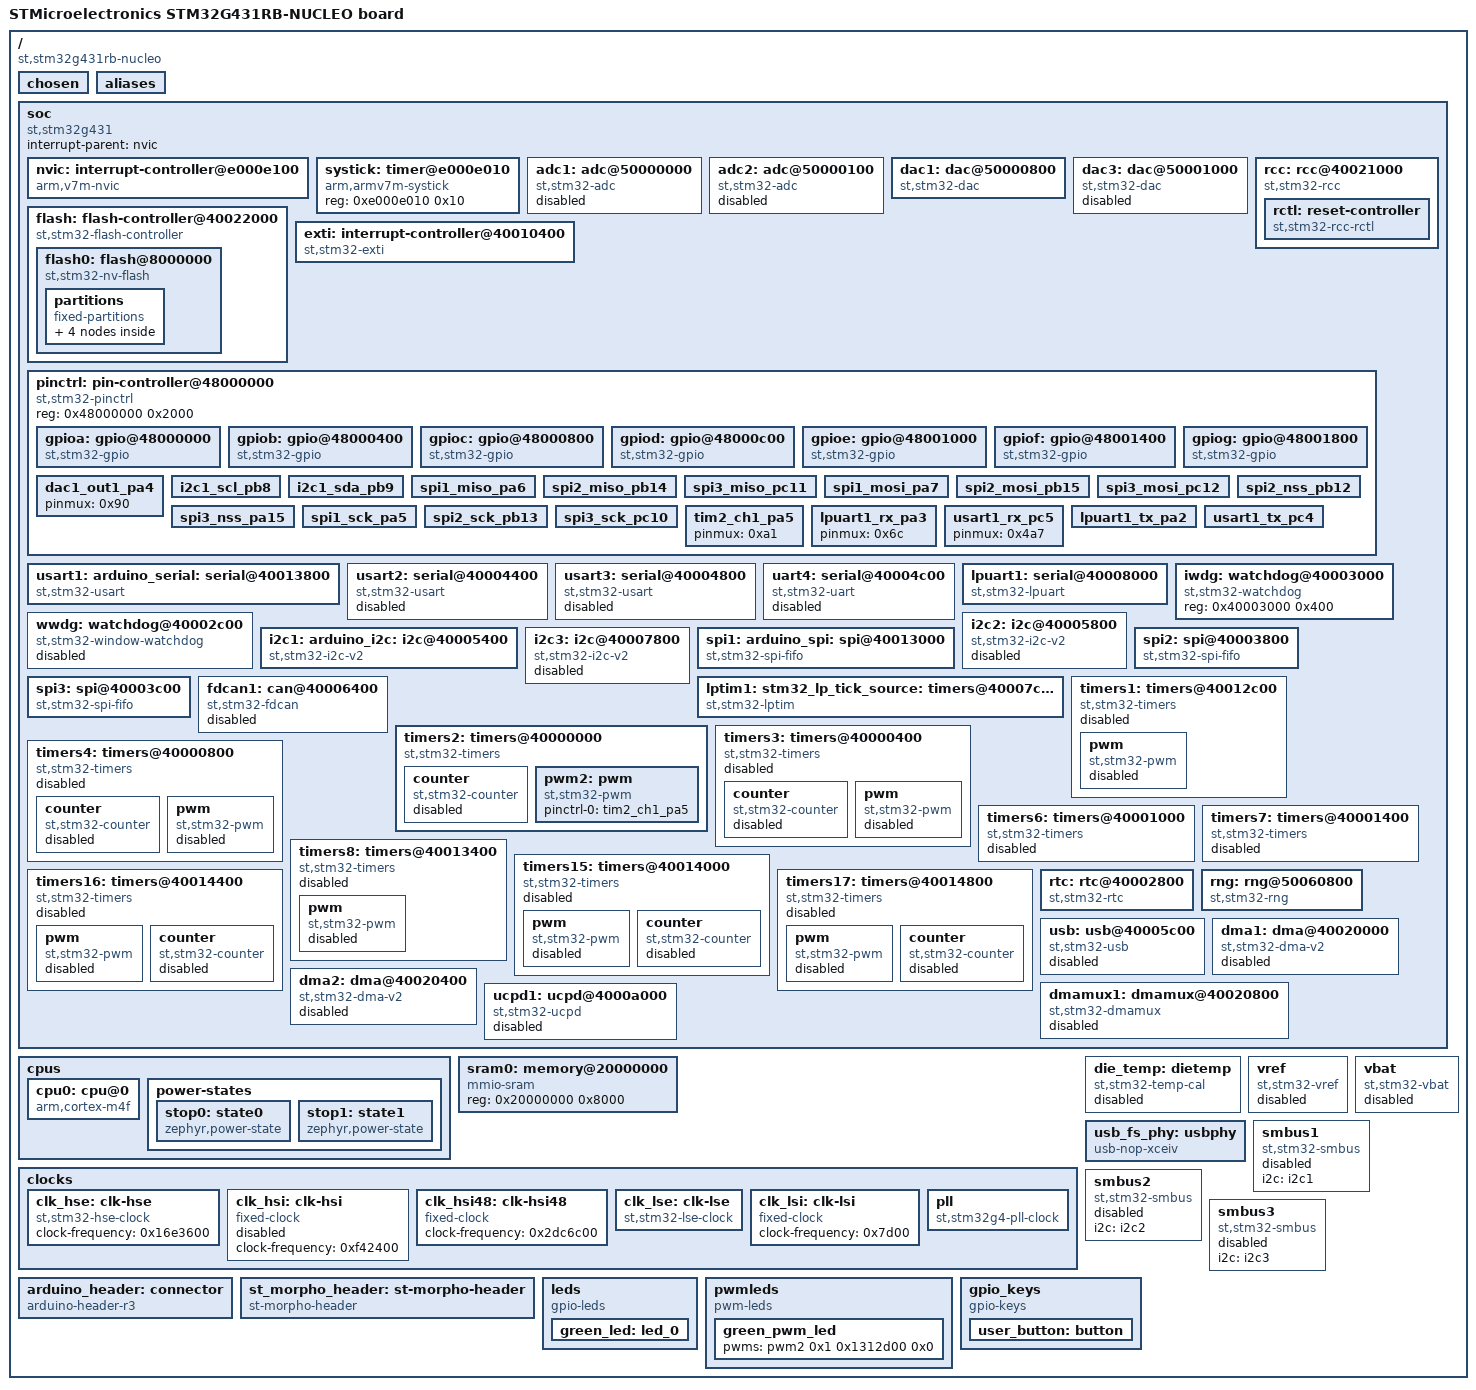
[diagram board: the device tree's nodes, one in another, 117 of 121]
/dts-v1/;

/* node '/' defined in zephyr\dts\common\skeleton.dtsi:9 */
/ {
	#address-cells = < 0x1 >;                              /* in zephyr\dts\common\skeleton.dtsi:10 */
	#size-cells = < 0x1 >;                                 /* in zephyr\dts\common\skeleton.dtsi:11 */
	model = "STMicroelectronics STM32G431RB-NUCLEO board"; /* in zephyr\boards\st\nucleo_g431rb\nucleo_g431rb.dts:15 */
	compatible = "st,stm32g431rb-nucleo";                  /* in zephyr\boards\st\nucleo_g431rb\nucleo_g431rb.dts:16 */

	/* node '/chosen' defined in zephyr\dts\common\skeleton.dtsi:12 */
	chosen {
		zephyr,entropy = &rng;                    /* in zephyr\dts\arm\st\g4\stm32g4.dtsi:24 */
		zephyr,flash-controller = &flash;         /* in zephyr\dts\arm\st\g4\stm32g4.dtsi:25 */
		zephyr,console = &lpuart1;                /* in zephyr\boards\st\nucleo_g431rb\nucleo_g431rb.dts:19 */
		zephyr,shell-uart = &lpuart1;             /* in zephyr\boards\st\nucleo_g431rb\nucleo_g431rb.dts:20 */
		zephyr,sram = &sram0;                     /* in zephyr\boards\st\nucleo_g431rb\nucleo_g431rb.dts:21 */
		zephyr,flash = &flash0;                   /* in zephyr\boards\st\nucleo_g431rb\nucleo_g431rb.dts:22 */
		zephyr,code-partition = &slot0_partition; /* in zephyr\boards\st\nucleo_g431rb\nucleo_g431rb.dts:23 */
	};

	/* node '/aliases' defined in zephyr\dts\common\skeleton.dtsi:13 */
	aliases {
		led0 = &green_led;         /* in zephyr\boards\st\nucleo_g431rb\nucleo_g431rb.dts:54 */
		mcuboot-led0 = &green_led; /* in zephyr\boards\st\nucleo_g431rb\nucleo_g431rb.dts:55 */
		pwm-led0 = &green_pwm_led; /* in zephyr\boards\st\nucleo_g431rb\nucleo_g431rb.dts:56 */
		sw0 = &user_button;        /* in zephyr\boards\st\nucleo_g431rb\nucleo_g431rb.dts:57 */
		watchdog0 = &iwdg;         /* in zephyr\boards\st\nucleo_g431rb\nucleo_g431rb.dts:58 */
	};

	/* node '/soc' defined in zephyr\dts\arm\armv7-m.dtsi:6 */
	soc {
		#address-cells = < 0x1 >;     /* in zephyr\dts\arm\armv7-m.dtsi:7 */
		#size-cells = < 0x1 >;        /* in zephyr\dts\arm\armv7-m.dtsi:8 */
		interrupt-parent = < &nvic >; /* in zephyr\dts\arm\armv7-m.dtsi:10 */
		ranges;                       /* in zephyr\dts\arm\armv7-m.dtsi:11 */
		compatible = "st,stm32g431",
		             "st,stm32g4",
		             "simple-bus";    /* in zephyr\dts\arm\st\g4\stm32g431.dtsi:11 */

		/* node '/soc/interrupt-controller@e000e100' defined in zephyr\dts\arm\armv7-m.dtsi:13 */
		nvic: interrupt-controller@e000e100 {
			#address-cells = < 0x1 >;            /* in zephyr\dts\arm\armv7-m.dtsi:14 */
			compatible = "arm,v7m-nvic";         /* in zephyr\dts\arm\armv7-m.dtsi:15 */
			reg = < 0xe000e100 0xc00 >;          /* in zephyr\dts\arm\armv7-m.dtsi:16 */
			interrupt-controller;                /* in zephyr\dts\arm\armv7-m.dtsi:17 */
			#interrupt-cells = < 0x2 >;          /* in zephyr\dts\arm\armv7-m.dtsi:18 */
			arm,num-irq-priority-bits = < 0x4 >; /* in zephyr\dts\arm\st\g4\stm32g4.dtsi:725 */
			phandle = < 0x1 >;                   /* in zephyr\dts\arm\armv7-m.dtsi:10 */
		};

		/* node '/soc/timer@e000e010' defined in zephyr\dts\arm\armv7-m.dtsi:21 */
		systick: timer@e000e010 {
			compatible = "arm,armv7m-systick"; /* in zephyr\dts\arm\armv7-m.dtsi:22 */
			reg = < 0xe000e010 0x10 >;         /* in zephyr\dts\arm\armv7-m.dtsi:23 */
		};

		/* node '/soc/adc@50000000' defined in zephyr\dts\arm\st\g4\stm32g4.dtsi:106 */
		adc1: adc@50000000 {
			compatible = "st,stm32-adc";                                /* in zephyr\dts\arm\st\g4\stm32g4.dtsi:107 */
			reg = < 0x50000000 0x100 >;                                 /* in zephyr\dts\arm\st\g4\stm32g4.dtsi:108 */
			clocks = < &rcc 0x4c 0x2000 >;                              /* in zephyr\dts\arm\st\g4\stm32g4.dtsi:109 */
			interrupts = < 0x12 0x0 >;                                  /* in zephyr\dts\arm\st\g4\stm32g4.dtsi:110 */
			status = "disabled";                                        /* in zephyr\dts\arm\st\g4\stm32g4.dtsi:111 */
			#io-channel-cells = < 0x1 >;                                /* in zephyr\dts\arm\st\g4\stm32g4.dtsi:112 */
			resolutions = < 0x60630c 0x51630c 0x42630c 0x33630c >;      /* in zephyr\dts\arm\st\g4\stm32g4.dtsi:113 */
			sampling-times = < 0x3 0x7 0xd 0x19 0x30 0x5d 0xf8 0x281 >; /* in zephyr\dts\arm\st\g4\stm32g4.dtsi:117 */
			st,adc-sequencer = "FULLY_CONFIGURABLE";                    /* in zephyr\dts\arm\st\g4\stm32g4.dtsi:118 */
			st,adc-oversampler = "OVERSAMPLER_MINIMAL";                 /* in zephyr\dts\arm\st\g4\stm32g4.dtsi:119 */
			phandle = < 0x1d >;                                         /* in zephyr\dts\arm\st\g4\stm32g4.dtsi:675 */
		};

		/* node '/soc/adc@50000100' defined in zephyr\dts\arm\st\g4\stm32g4.dtsi:122 */
		adc2: adc@50000100 {
			compatible = "st,stm32-adc";                                /* in zephyr\dts\arm\st\g4\stm32g4.dtsi:123 */
			reg = < 0x50000100 0x100 >;                                 /* in zephyr\dts\arm\st\g4\stm32g4.dtsi:124 */
			clocks = < &rcc 0x4c 0x2000 >;                              /* in zephyr\dts\arm\st\g4\stm32g4.dtsi:125 */
			interrupts = < 0x12 0x0 >;                                  /* in zephyr\dts\arm\st\g4\stm32g4.dtsi:126 */
			status = "disabled";                                        /* in zephyr\dts\arm\st\g4\stm32g4.dtsi:127 */
			#io-channel-cells = < 0x1 >;                                /* in zephyr\dts\arm\st\g4\stm32g4.dtsi:128 */
			resolutions = < 0x60630c 0x51630c 0x42630c 0x33630c >;      /* in zephyr\dts\arm\st\g4\stm32g4.dtsi:129 */
			sampling-times = < 0x3 0x7 0xd 0x19 0x30 0x5d 0xf8 0x281 >; /* in zephyr\dts\arm\st\g4\stm32g4.dtsi:133 */
			st,adc-sequencer = "FULLY_CONFIGURABLE";                    /* in zephyr\dts\arm\st\g4\stm32g4.dtsi:134 */
			st,adc-oversampler = "OVERSAMPLER_MINIMAL";                 /* in zephyr\dts\arm\st\g4\stm32g4.dtsi:135 */
		};

		/* node '/soc/dac@50000800' defined in zephyr\dts\arm\st\g4\stm32g4.dtsi:138 */
		dac1: dac@50000800 {
			compatible = "st,stm32-dac";    /* in zephyr\dts\arm\st\g4\stm32g4.dtsi:139 */
			reg = < 0x50000800 0x400 >;     /* in zephyr\dts\arm\st\g4\stm32g4.dtsi:140 */
			clocks = < &rcc 0x4c 0x10000 >; /* in zephyr\dts\arm\st\g4\stm32g4.dtsi:141 */
			#io-channel-cells = < 0x1 >;    /* in zephyr\dts\arm\st\g4\stm32g4.dtsi:143 */
			status = "okay";                /* in zephyr\boards\st\nucleo_g431rb\nucleo_g431rb.dts:201 */
			pinctrl-0 = < &dac1_out1_pa4 >; /* in zephyr\boards\st\nucleo_g431rb\nucleo_g431rb.dts:202 */
			pinctrl-names = "default";      /* in zephyr\boards\st\nucleo_g431rb\nucleo_g431rb.dts:203 */
		};

		/* node '/soc/dac@50001000' defined in zephyr\dts\arm\st\g4\stm32g4.dtsi:146 */
		dac3: dac@50001000 {
			compatible = "st,stm32-dac";    /* in zephyr\dts\arm\st\g4\stm32g4.dtsi:147 */
			reg = < 0x50001000 0x400 >;     /* in zephyr\dts\arm\st\g4\stm32g4.dtsi:148 */
			clocks = < &rcc 0x4c 0x40000 >; /* in zephyr\dts\arm\st\g4\stm32g4.dtsi:149 */
			status = "disabled";            /* in zephyr\dts\arm\st\g4\stm32g4.dtsi:150 */
			#io-channel-cells = < 0x1 >;    /* in zephyr\dts\arm\st\g4\stm32g4.dtsi:151 */
		};

		/* node '/soc/flash-controller@40022000' defined in zephyr\dts\arm\st\g4\stm32g4.dtsi:154 */
		flash: flash-controller@40022000 {
			compatible = "st,stm32-flash-controller",
			             "st,stm32g4-flash-controller"; /* in zephyr\dts\arm\st\g4\stm32g4.dtsi:155 */
			reg = < 0x40022000 0x400 >;                 /* in zephyr\dts\arm\st\g4\stm32g4.dtsi:156 */
			interrupts = < 0x3 0x0 >;                   /* in zephyr\dts\arm\st\g4\stm32g4.dtsi:157 */
			clocks = < &rcc 0x48 0x100 >;               /* in zephyr\dts\arm\st\g4\stm32g4.dtsi:158 */
			#address-cells = < 0x1 >;                   /* in zephyr\dts\arm\st\g4\stm32g4.dtsi:160 */
			#size-cells = < 0x1 >;                      /* in zephyr\dts\arm\st\g4\stm32g4.dtsi:161 */

			/* node '/soc/flash-controller@40022000/flash@8000000' defined in zephyr\dts\arm\st\g4\stm32g4.dtsi:163 */
			flash0: flash@8000000 {
				compatible = "st,stm32-nv-flash",
				             "soc-nv-flash";      /* in zephyr\dts\arm\st\g4\stm32g4.dtsi:164 */
				write-block-size = < 0x8 >;       /* in zephyr\dts\arm\st\g4\stm32g4.dtsi:166 */
				erase-block-size = < 0x800 >;     /* in zephyr\dts\arm\st\g4\stm32g4.dtsi:167 */
				max-erase-time = < 0x19 >;        /* in zephyr\dts\arm\st\g4\stm32g4.dtsi:169 */
				reg = < 0x8000000 0x20000 >;      /* in zephyr\dts\arm\st\g4\stm32g431Xb.dtsi:15 */

				/* node '/soc/flash-controller@40022000/flash@8000000/partitions' defined in zephyr\boards\st\nucleo_g431rb\nucleo_g431rb.dts:168 */
				partitions {
					compatible = "fixed-partitions"; /* in zephyr\boards\st\nucleo_g431rb\nucleo_g431rb.dts:169 */
					#address-cells = < 0x1 >;        /* in zephyr\boards\st\nucleo_g431rb\nucleo_g431rb.dts:170 */
					#size-cells = < 0x1 >;           /* in zephyr\boards\st\nucleo_g431rb\nucleo_g431rb.dts:171 */

					/* node '/soc/flash-controller@40022000/flash@8000000/partitions/partition@0' defined in zephyr\boards\st\nucleo_g431rb\nucleo_g431rb.dts:173 */
					boot_partition: partition@0 {
						label = "mcuboot";    /* in zephyr\boards\st\nucleo_g431rb\nucleo_g431rb.dts:174 */
						reg = < 0x0 0x8800 >; /* in zephyr\boards\st\nucleo_g431rb\nucleo_g431rb.dts:175 */
					};

					/* node '/soc/flash-controller@40022000/flash@8000000/partitions/partition@8800' defined in zephyr\boards\st\nucleo_g431rb\nucleo_g431rb.dts:178 */
					slot0_partition: partition@8800 {
						label = "image-0";       /* in zephyr\boards\st\nucleo_g431rb\nucleo_g431rb.dts:179 */
						reg = < 0x8800 0xc000 >; /* in zephyr\boards\st\nucleo_g431rb\nucleo_g431rb.dts:180 */
					};

					/* node '/soc/flash-controller@40022000/flash@8000000/partitions/partition@14800' defined in zephyr\boards\st\nucleo_g431rb\nucleo_g431rb.dts:183 */
					slot1_partition: partition@14800 {
						label = "image-1";        /* in zephyr\boards\st\nucleo_g431rb\nucleo_g431rb.dts:184 */
						reg = < 0x14800 0xa800 >; /* in zephyr\boards\st\nucleo_g431rb\nucleo_g431rb.dts:185 */
					};

					/* node '/soc/flash-controller@40022000/flash@8000000/partitions/partition@1f000' defined in zephyr\boards\st\nucleo_g431rb\nucleo_g431rb.dts:189 */
					storage_partition: partition@1f000 {
						label = "storage";        /* in zephyr\boards\st\nucleo_g431rb\nucleo_g431rb.dts:190 */
						reg = < 0x1f000 0x1000 >; /* in zephyr\boards\st\nucleo_g431rb\nucleo_g431rb.dts:191 */
					};
				};
			};
		};

		/* node '/soc/rcc@40021000' defined in zephyr\dts\arm\st\g4\stm32g4.dtsi:173 */
		rcc: rcc@40021000 {
			compatible = "st,stm32-rcc";     /* in zephyr\dts\arm\st\g4\stm32g4.dtsi:174 */
			#clock-cells = < 0x2 >;          /* in zephyr\dts\arm\st\g4\stm32g4.dtsi:175 */
			reg = < 0x40021000 0x400 >;      /* in zephyr\dts\arm\st\g4\stm32g4.dtsi:176 */
			undershoot-prevention;           /* in zephyr\dts\arm\st\g4\stm32g4.dtsi:177 */
			clocks = < &pll >;               /* in zephyr\boards\st\nucleo_g431rb\nucleo_g431rb.dts:90 */
			clock-frequency = < 0xa21fe80 >; /* in zephyr\boards\st\nucleo_g431rb\nucleo_g431rb.dts:91 */
			ahb-prescaler = < 0x1 >;         /* in zephyr\boards\st\nucleo_g431rb\nucleo_g431rb.dts:92 */
			apb1-prescaler = < 0x1 >;        /* in zephyr\boards\st\nucleo_g431rb\nucleo_g431rb.dts:93 */
			apb2-prescaler = < 0x1 >;        /* in zephyr\boards\st\nucleo_g431rb\nucleo_g431rb.dts:94 */
			phandle = < 0x2 >;               /* in zephyr\dts\arm\st\g4\stm32g4.dtsi:109 */

			/* node '/soc/rcc@40021000/reset-controller' defined in zephyr\dts\arm\st\g4\stm32g4.dtsi:179 */
			rctl: reset-controller {
				compatible = "st,stm32-rcc-rctl"; /* in zephyr\dts\arm\st\g4\stm32g4.dtsi:180 */
				#reset-cells = < 0x1 >;           /* in zephyr\dts\arm\st\g4\stm32g4.dtsi:181 */
				phandle = < 0x5 >;                /* in zephyr\dts\arm\st\g4\stm32g4.dtsi:267 */
			};
		};

		/* node '/soc/interrupt-controller@40010400' defined in zephyr\dts\arm\st\g4\stm32g4.dtsi:185 */
		exti: interrupt-controller@40010400 {
			compatible = "st,stm32-exti";  /* in zephyr\dts\arm\st\g4\stm32g4.dtsi:186 */
			interrupt-controller;          /* in zephyr\dts\arm\st\g4\stm32g4.dtsi:187 */
			#interrupt-cells = < 0x1 >;    /* in zephyr\dts\arm\st\g4\stm32g4.dtsi:188 */
			#address-cells = < 0x1 >;      /* in zephyr\dts\arm\st\g4\stm32g4.dtsi:189 */
			reg = < 0x40010400 0x400 >;    /* in zephyr\dts\arm\st\g4\stm32g4.dtsi:190 */
			num-lines = < 0x10 >;          /* in zephyr\dts\arm\st\g4\stm32g4.dtsi:191 */
			interrupts = < 0x6 0x0 >,
			             < 0x7 0x0 >,
			             < 0x8 0x0 >,
			             < 0x9 0x0 >,
			             < 0xa 0x0 >,
			             < 0x17 0x0 >,
			             < 0x28 0x0 >;     /* in zephyr\dts\arm\st\g4\stm32g4.dtsi:192 */
			interrupt-names = "line0",
			                  "line1",
			                  "line2-TSC",
			                  "line3",
			                  "line4",
			                  "line5-9",
			                  "line10-15"; /* in zephyr\dts\arm\st\g4\stm32g4.dtsi:194 */
			line-ranges = < 0x0 0x1 >,
			              < 0x1 0x1 >,
			              < 0x2 0x1 >,
			              < 0x3 0x1 >,
			              < 0x4 0x1 >,
			              < 0x5 0x5 >,
			              < 0xa 0x6 >;     /* in zephyr\dts\arm\st\g4\stm32g4.dtsi:196 */
		};

		/* node '/soc/pin-controller@48000000' defined in zephyr\dts\arm\st\g4\stm32g4.dtsi:200 */
		pinctrl: pin-controller@48000000 {
			compatible = "st,stm32-pinctrl"; /* in zephyr\dts\arm\st\g4\stm32g4.dtsi:201 */
			#address-cells = < 0x1 >;        /* in zephyr\dts\arm\st\g4\stm32g4.dtsi:202 */
			#size-cells = < 0x1 >;           /* in zephyr\dts\arm\st\g4\stm32g4.dtsi:203 */
			reg = < 0x48000000 0x2000 >;     /* in zephyr\dts\arm\st\g4\stm32g4.dtsi:204 */

			/* node '/soc/pin-controller@48000000/gpio@48000000' defined in zephyr\dts\arm\st\g4\stm32g4.dtsi:206 */
			gpioa: gpio@48000000 {
				compatible = "st,stm32-gpio"; /* in zephyr\dts\arm\st\g4\stm32g4.dtsi:207 */
				gpio-controller;              /* in zephyr\dts\arm\st\g4\stm32g4.dtsi:208 */
				#gpio-cells = < 0x2 >;        /* in zephyr\dts\arm\st\g4\stm32g4.dtsi:209 */
				reg = < 0x48000000 0x400 >;   /* in zephyr\dts\arm\st\g4\stm32g4.dtsi:210 */
				clocks = < &rcc 0x4c 0x1 >;   /* in zephyr\dts\arm\st\g4\stm32g4.dtsi:211 */
				phandle = < 0x21 >;           /* in zephyr\boards\st\nucleo_g431rb\arduino_r3_connector.dtsi:13 */
			};

			/* node '/soc/pin-controller@48000000/gpio@48000400' defined in zephyr\dts\arm\st\g4\stm32g4.dtsi:214 */
			gpiob: gpio@48000400 {
				compatible = "st,stm32-gpio"; /* in zephyr\dts\arm\st\g4\stm32g4.dtsi:215 */
				gpio-controller;              /* in zephyr\dts\arm\st\g4\stm32g4.dtsi:216 */
				#gpio-cells = < 0x2 >;        /* in zephyr\dts\arm\st\g4\stm32g4.dtsi:217 */
				reg = < 0x48000400 0x400 >;   /* in zephyr\dts\arm\st\g4\stm32g4.dtsi:218 */
				clocks = < &rcc 0x4c 0x2 >;   /* in zephyr\dts\arm\st\g4\stm32g4.dtsi:219 */
				phandle = < 0xf >;            /* in zephyr\boards\st\nucleo_g431rb\nucleo_g431rb.dts:126 */
			};

			/* node '/soc/pin-controller@48000000/gpio@48000800' defined in zephyr\dts\arm\st\g4\stm32g4.dtsi:222 */
			gpioc: gpio@48000800 {
				compatible = "st,stm32-gpio"; /* in zephyr\dts\arm\st\g4\stm32g4.dtsi:223 */
				gpio-controller;              /* in zephyr\dts\arm\st\g4\stm32g4.dtsi:224 */
				#gpio-cells = < 0x2 >;        /* in zephyr\dts\arm\st\g4\stm32g4.dtsi:225 */
				reg = < 0x48000800 0x400 >;   /* in zephyr\dts\arm\st\g4\stm32g4.dtsi:226 */
				clocks = < &rcc 0x4c 0x4 >;   /* in zephyr\dts\arm\st\g4\stm32g4.dtsi:227 */
				phandle = < 0x22 >;           /* in zephyr\boards\st\nucleo_g431rb\arduino_r3_connector.dtsi:13 */
			};

			/* node '/soc/pin-controller@48000000/gpio@48000c00' defined in zephyr\dts\arm\st\g4\stm32g4.dtsi:230 */
			gpiod: gpio@48000c00 {
				compatible = "st,stm32-gpio"; /* in zephyr\dts\arm\st\g4\stm32g4.dtsi:231 */
				gpio-controller;              /* in zephyr\dts\arm\st\g4\stm32g4.dtsi:232 */
				#gpio-cells = < 0x2 >;        /* in zephyr\dts\arm\st\g4\stm32g4.dtsi:233 */
				reg = < 0x48000c00 0x400 >;   /* in zephyr\dts\arm\st\g4\stm32g4.dtsi:234 */
				clocks = < &rcc 0x4c 0x8 >;   /* in zephyr\dts\arm\st\g4\stm32g4.dtsi:235 */
				phandle = < 0x23 >;           /* in zephyr\boards\st\nucleo_g431rb\st_morpho_connector.dtsi:15 */
			};

			/* node '/soc/pin-controller@48000000/gpio@48001000' defined in zephyr\dts\arm\st\g4\stm32g4.dtsi:238 */
			gpioe: gpio@48001000 {
				compatible = "st,stm32-gpio"; /* in zephyr\dts\arm\st\g4\stm32g4.dtsi:239 */
				gpio-controller;              /* in zephyr\dts\arm\st\g4\stm32g4.dtsi:240 */
				#gpio-cells = < 0x2 >;        /* in zephyr\dts\arm\st\g4\stm32g4.dtsi:241 */
				reg = < 0x48001000 0x400 >;   /* in zephyr\dts\arm\st\g4\stm32g4.dtsi:242 */
				clocks = < &rcc 0x4c 0x10 >;  /* in zephyr\dts\arm\st\g4\stm32g4.dtsi:243 */
			};

			/* node '/soc/pin-controller@48000000/gpio@48001400' defined in zephyr\dts\arm\st\g4\stm32g4.dtsi:246 */
			gpiof: gpio@48001400 {
				compatible = "st,stm32-gpio"; /* in zephyr\dts\arm\st\g4\stm32g4.dtsi:247 */
				gpio-controller;              /* in zephyr\dts\arm\st\g4\stm32g4.dtsi:248 */
				#gpio-cells = < 0x2 >;        /* in zephyr\dts\arm\st\g4\stm32g4.dtsi:249 */
				reg = < 0x48001400 0x400 >;   /* in zephyr\dts\arm\st\g4\stm32g4.dtsi:250 */
				clocks = < &rcc 0x4c 0x20 >;  /* in zephyr\dts\arm\st\g4\stm32g4.dtsi:251 */
				phandle = < 0x24 >;           /* in zephyr\boards\st\nucleo_g431rb\st_morpho_connector.dtsi:15 */
			};

			/* node '/soc/pin-controller@48000000/gpio@48001800' defined in zephyr\dts\arm\st\g4\stm32g4.dtsi:254 */
			gpiog: gpio@48001800 {
				compatible = "st,stm32-gpio"; /* in zephyr\dts\arm\st\g4\stm32g4.dtsi:255 */
				gpio-controller;              /* in zephyr\dts\arm\st\g4\stm32g4.dtsi:256 */
				#gpio-cells = < 0x2 >;        /* in zephyr\dts\arm\st\g4\stm32g4.dtsi:257 */
				reg = < 0x48001800 0x400 >;   /* in zephyr\dts\arm\st\g4\stm32g4.dtsi:258 */
				clocks = < &rcc 0x4c 0x40 >;  /* in zephyr\dts\arm\st\g4\stm32g4.dtsi:259 */
			};

			/* node '/soc/pin-controller@48000000/dac1_out1_pa4' defined in modules\hal\stm32\dts\st\g4\stm32g431r(6-8-b)tx-pinctrl.dtsi:347 */
			dac1_out1_pa4: dac1_out1_pa4 {
				pinmux = < 0x90 >; /* in modules\hal\stm32\dts\st\g4\stm32g431r(6-8-b)tx-pinctrl.dtsi:348 */
				phandle = < 0x3 >; /* in zephyr\boards\st\nucleo_g431rb\nucleo_g431rb.dts:202 */
			};

			/* node '/soc/pin-controller@48000000/i2c1_scl_pb8' defined in modules\hal\stm32\dts\st\g4\stm32g431r(6-8-b)tx-pinctrl.dtsi:389 */
			i2c1_scl_pb8: i2c1_scl_pb8 {
				pinmux = < 0x304 >; /* in modules\hal\stm32\dts\st\g4\stm32g431r(6-8-b)tx-pinctrl.dtsi:390 */
				bias-pull-up;       /* in modules\hal\stm32\dts\st\g4\stm32g431r(6-8-b)tx-pinctrl.dtsi:391 */
				drive-open-drain;   /* in modules\hal\stm32\dts\st\g4\stm32g431r(6-8-b)tx-pinctrl.dtsi:392 */
				phandle = < 0xa >;  /* in zephyr\boards\st\nucleo_g431rb\nucleo_g431rb.dts:118 */
			};

			/* node '/soc/pin-controller@48000000/i2c1_sda_pb9' defined in modules\hal\stm32\dts\st\g4\stm32g431r(6-8-b)tx-pinctrl.dtsi:433 */
			i2c1_sda_pb9: i2c1_sda_pb9 {
				pinmux = < 0x324 >; /* in modules\hal\stm32\dts\st\g4\stm32g431r(6-8-b)tx-pinctrl.dtsi:434 */
				bias-pull-up;       /* in modules\hal\stm32\dts\st\g4\stm32g431r(6-8-b)tx-pinctrl.dtsi:435 */
				drive-open-drain;   /* in modules\hal\stm32\dts\st\g4\stm32g431r(6-8-b)tx-pinctrl.dtsi:436 */
				phandle = < 0xb >;  /* in zephyr\boards\st\nucleo_g431rb\nucleo_g431rb.dts:118 */
			};

			/* node '/soc/pin-controller@48000000/spi1_miso_pa6' defined in modules\hal\stm32\dts\st\g4\stm32g431r(6-8-b)tx-pinctrl.dtsi:706 */
			spi1_miso_pa6: spi1_miso_pa6 {
				pinmux = < 0xc5 >; /* in modules\hal\stm32\dts\st\g4\stm32g431r(6-8-b)tx-pinctrl.dtsi:707 */
				bias-pull-down;    /* in modules\hal\stm32\dts\st\g4\stm32g431r(6-8-b)tx-pinctrl.dtsi:708 */
				phandle = < 0xd >; /* in zephyr\boards\st\nucleo_g431rb\nucleo_g431rb.dts:124 */
			};

			/* node '/soc/pin-controller@48000000/spi2_miso_pb14' defined in modules\hal\stm32\dts\st\g4\stm32g431r(6-8-b)tx-pinctrl.dtsi:721 */
			spi2_miso_pb14: spi2_miso_pb14 {
				pinmux = < 0x3c5 >; /* in modules\hal\stm32\dts\st\g4\stm32g431r(6-8-b)tx-pinctrl.dtsi:722 */
				bias-pull-down;     /* in modules\hal\stm32\dts\st\g4\stm32g431r(6-8-b)tx-pinctrl.dtsi:723 */
				phandle = < 0x12 >; /* in zephyr\boards\st\nucleo_g431rb\nucleo_g431rb.dts:131 */
			};

			/* node '/soc/pin-controller@48000000/spi3_miso_pc11' defined in modules\hal\stm32\dts\st\g4\stm32g431r(6-8-b)tx-pinctrl.dtsi:731 */
			spi3_miso_pc11: spi3_miso_pc11 {
				pinmux = < 0x566 >; /* in modules\hal\stm32\dts\st\g4\stm32g431r(6-8-b)tx-pinctrl.dtsi:732 */
				bias-pull-down;     /* in modules\hal\stm32\dts\st\g4\stm32g431r(6-8-b)tx-pinctrl.dtsi:733 */
				phandle = < 0x16 >; /* in zephyr\boards\st\nucleo_g431rb\nucleo_g431rb.dts:139 */
			};

			/* node '/soc/pin-controller@48000000/spi1_mosi_pa7' defined in modules\hal\stm32\dts\st\g4\stm32g431r(6-8-b)tx-pinctrl.dtsi:738 */
			spi1_mosi_pa7: spi1_mosi_pa7 {
				pinmux = < 0xe5 >; /* in modules\hal\stm32\dts\st\g4\stm32g431r(6-8-b)tx-pinctrl.dtsi:739 */
				bias-pull-down;    /* in modules\hal\stm32\dts\st\g4\stm32g431r(6-8-b)tx-pinctrl.dtsi:740 */
				phandle = < 0xe >; /* in zephyr\boards\st\nucleo_g431rb\nucleo_g431rb.dts:124 */
			};

			/* node '/soc/pin-controller@48000000/spi2_mosi_pb15' defined in modules\hal\stm32\dts\st\g4\stm32g431r(6-8-b)tx-pinctrl.dtsi:753 */
			spi2_mosi_pb15: spi2_mosi_pb15 {
				pinmux = < 0x3e5 >; /* in modules\hal\stm32\dts\st\g4\stm32g431r(6-8-b)tx-pinctrl.dtsi:754 */
				bias-pull-down;     /* in modules\hal\stm32\dts\st\g4\stm32g431r(6-8-b)tx-pinctrl.dtsi:755 */
				phandle = < 0x13 >; /* in zephyr\boards\st\nucleo_g431rb\nucleo_g431rb.dts:131 */
			};

			/* node '/soc/pin-controller@48000000/spi3_mosi_pc12' defined in modules\hal\stm32\dts\st\g4\stm32g431r(6-8-b)tx-pinctrl.dtsi:763 */
			spi3_mosi_pc12: spi3_mosi_pc12 {
				pinmux = < 0x586 >; /* in modules\hal\stm32\dts\st\g4\stm32g431r(6-8-b)tx-pinctrl.dtsi:764 */
				bias-pull-down;     /* in modules\hal\stm32\dts\st\g4\stm32g431r(6-8-b)tx-pinctrl.dtsi:765 */
				phandle = < 0x17 >; /* in zephyr\boards\st\nucleo_g431rb\nucleo_g431rb.dts:139 */
			};

			/* node '/soc/pin-controller@48000000/spi2_nss_pb12' defined in modules\hal\stm32\dts\st\g4\stm32g431r(6-8-b)tx-pinctrl.dtsi:780 */
			spi2_nss_pb12: spi2_nss_pb12 {
				pinmux = < 0x385 >; /* in modules\hal\stm32\dts\st\g4\stm32g431r(6-8-b)tx-pinctrl.dtsi:781 */
				bias-pull-up;       /* in modules\hal\stm32\dts\st\g4\stm32g431r(6-8-b)tx-pinctrl.dtsi:782 */
				phandle = < 0x10 >; /* in zephyr\boards\st\nucleo_g431rb\nucleo_g431rb.dts:131 */
			};

			/* node '/soc/pin-controller@48000000/spi3_nss_pa15' defined in modules\hal\stm32\dts\st\g4\stm32g431r(6-8-b)tx-pinctrl.dtsi:795 */
			spi3_nss_pa15: spi3_nss_pa15 {
				pinmux = < 0x1e6 >; /* in modules\hal\stm32\dts\st\g4\stm32g431r(6-8-b)tx-pinctrl.dtsi:796 */
				bias-pull-up;       /* in modules\hal\stm32\dts\st\g4\stm32g431r(6-8-b)tx-pinctrl.dtsi:797 */
				phandle = < 0x14 >; /* in zephyr\boards\st\nucleo_g431rb\nucleo_g431rb.dts:139 */
			};

			/* node '/soc/pin-controller@48000000/spi1_sck_pa5' defined in modules\hal\stm32\dts\st\g4\stm32g431r(6-8-b)tx-pinctrl.dtsi:802 */
			spi1_sck_pa5: spi1_sck_pa5 {
				pinmux = < 0xa5 >;             /* in modules\hal\stm32\dts\st\g4\stm32g431r(6-8-b)tx-pinctrl.dtsi:803 */
				bias-pull-down;                /* in modules\hal\stm32\dts\st\g4\stm32g431r(6-8-b)tx-pinctrl.dtsi:804 */
				slew-rate = "very-high-speed"; /* in modules\hal\stm32\dts\st\g4\stm32g431r(6-8-b)tx-pinctrl.dtsi:805 */
				phandle = < 0xc >;             /* in zephyr\boards\st\nucleo_g431rb\nucleo_g431rb.dts:124 */
			};

			/* node '/soc/pin-controller@48000000/spi2_sck_pb13' defined in modules\hal\stm32\dts\st\g4\stm32g431r(6-8-b)tx-pinctrl.dtsi:814 */
			spi2_sck_pb13: spi2_sck_pb13 {
				pinmux = < 0x3a5 >;            /* in modules\hal\stm32\dts\st\g4\stm32g431r(6-8-b)tx-pinctrl.dtsi:815 */
				bias-pull-down;                /* in modules\hal\stm32\dts\st\g4\stm32g431r(6-8-b)tx-pinctrl.dtsi:816 */
				slew-rate = "very-high-speed"; /* in modules\hal\stm32\dts\st\g4\stm32g431r(6-8-b)tx-pinctrl.dtsi:817 */
				phandle = < 0x11 >;            /* in zephyr\boards\st\nucleo_g431rb\nucleo_g431rb.dts:131 */
			};

			/* node '/soc/pin-controller@48000000/spi3_sck_pc10' defined in modules\hal\stm32\dts\st\g4\stm32g431r(6-8-b)tx-pinctrl.dtsi:832 */
			spi3_sck_pc10: spi3_sck_pc10 {
				pinmux = < 0x546 >;            /* in modules\hal\stm32\dts\st\g4\stm32g431r(6-8-b)tx-pinctrl.dtsi:833 */
				bias-pull-down;                /* in modules\hal\stm32\dts\st\g4\stm32g431r(6-8-b)tx-pinctrl.dtsi:834 */
				slew-rate = "very-high-speed"; /* in modules\hal\stm32\dts\st\g4\stm32g431r(6-8-b)tx-pinctrl.dtsi:835 */
				phandle = < 0x15 >;            /* in zephyr\boards\st\nucleo_g431rb\nucleo_g431rb.dts:139 */
			};

			/* node '/soc/pin-controller@48000000/tim2_ch1_pa5' defined in modules\hal\stm32\dts\st\g4\stm32g431r(6-8-b)tx-pinctrl.dtsi:1022 */
			tim2_ch1_pa5: tim2_ch1_pa5 {
				pinmux = < 0xa1 >;  /* in modules\hal\stm32\dts\st\g4\stm32g431r(6-8-b)tx-pinctrl.dtsi:1023 */
				phandle = < 0x18 >; /* in zephyr\boards\st\nucleo_g431rb\nucleo_g431rb.dts:150 */
			};

			/* node '/soc/pin-controller@48000000/lpuart1_rx_pa3' defined in modules\hal\stm32\dts\st\g4\stm32g431r(6-8-b)tx-pinctrl.dtsi:1369 */
			lpuart1_rx_pa3: lpuart1_rx_pa3 {
				pinmux = < 0x6c >; /* in modules\hal\stm32\dts\st\g4\stm32g431r(6-8-b)tx-pinctrl.dtsi:1370 */
				phandle = < 0x9 >; /* in zephyr\boards\st\nucleo_g431rb\nucleo_g431rb.dts:111 */
			};

			/* node '/soc/pin-controller@48000000/usart1_rx_pc5' defined in modules\hal\stm32\dts\st\g4\stm32g431r(6-8-b)tx-pinctrl.dtsi:1389 */
			usart1_rx_pc5: usart1_rx_pc5 {
				pinmux = < 0x4a7 >; /* in modules\hal\stm32\dts\st\g4\stm32g431r(6-8-b)tx-pinctrl.dtsi:1390 */
				phandle = < 0x7 >;  /* in zephyr\boards\st\nucleo_g431rb\nucleo_g431rb.dts:104 */
			};

			/* node '/soc/pin-controller@48000000/lpuart1_tx_pa2' defined in modules\hal\stm32\dts\st\g4\stm32g431r(6-8-b)tx-pinctrl.dtsi:1423 */
			lpuart1_tx_pa2: lpuart1_tx_pa2 {
				pinmux = < 0x4c >; /* in modules\hal\stm32\dts\st\g4\stm32g431r(6-8-b)tx-pinctrl.dtsi:1424 */
				bias-pull-up;      /* in modules\hal\stm32\dts\st\g4\stm32g431r(6-8-b)tx-pinctrl.dtsi:1425 */
				phandle = < 0x8 >; /* in zephyr\boards\st\nucleo_g431rb\nucleo_g431rb.dts:111 */
			};

			/* node '/soc/pin-controller@48000000/usart1_tx_pc4' defined in modules\hal\stm32\dts\st\g4\stm32g431r(6-8-b)tx-pinctrl.dtsi:1448 */
			usart1_tx_pc4: usart1_tx_pc4 {
				pinmux = < 0x487 >; /* in modules\hal\stm32\dts\st\g4\stm32g431r(6-8-b)tx-pinctrl.dtsi:1449 */
				bias-pull-up;       /* in modules\hal\stm32\dts\st\g4\stm32g431r(6-8-b)tx-pinctrl.dtsi:1450 */
				phandle = < 0x6 >;  /* in zephyr\boards\st\nucleo_g431rb\nucleo_g431rb.dts:104 */
			};
		};

		/* node '/soc/serial@40013800' defined in zephyr\dts\arm\st\g4\stm32g4.dtsi:263 */
		usart1: arduino_serial: serial@40013800 {
			compatible = "st,stm32-usart",
			             "st,stm32-uart";                  /* in zephyr\dts\arm\st\g4\stm32g4.dtsi:264 */
			reg = < 0x40013800 0x400 >;                    /* in zephyr\dts\arm\st\g4\stm32g4.dtsi:265 */
			clocks = < &rcc 0x60 0x4000 >;                 /* in zephyr\dts\arm\st\g4\stm32g4.dtsi:266 */
			resets = < &rctl 0x80e >;                      /* in zephyr\dts\arm\st\g4\stm32g4.dtsi:267 */
			interrupts = < 0x25 0x0 >;                     /* in zephyr\dts\arm\st\g4\stm32g4.dtsi:268 */
			pinctrl-0 = < &usart1_tx_pc4 &usart1_rx_pc5 >; /* in zephyr\boards\st\nucleo_g431rb\nucleo_g431rb.dts:104 */
			pinctrl-names = "default";                     /* in zephyr\boards\st\nucleo_g431rb\nucleo_g431rb.dts:105 */
			current-speed = < 0x1c200 >;                   /* in zephyr\boards\st\nucleo_g431rb\nucleo_g431rb.dts:106 */
			status = "okay";                               /* in zephyr\boards\st\nucleo_g431rb\nucleo_g431rb.dts:107 */
		};

		/* node '/soc/serial@40004400' defined in zephyr\dts\arm\st\g4\stm32g4.dtsi:272 */
		usart2: serial@40004400 {
			compatible = "st,stm32-usart",
			             "st,stm32-uart";   /* in zephyr\dts\arm\st\g4\stm32g4.dtsi:273 */
			reg = < 0x40004400 0x400 >;     /* in zephyr\dts\arm\st\g4\stm32g4.dtsi:274 */
			clocks = < &rcc 0x58 0x20000 >; /* in zephyr\dts\arm\st\g4\stm32g4.dtsi:275 */
			resets = < &rctl 0x711 >;       /* in zephyr\dts\arm\st\g4\stm32g4.dtsi:276 */
			interrupts = < 0x26 0x0 >;      /* in zephyr\dts\arm\st\g4\stm32g4.dtsi:277 */
			status = "disabled";            /* in zephyr\dts\arm\st\g4\stm32g4.dtsi:278 */
		};

		/* node '/soc/serial@40004800' defined in zephyr\dts\arm\st\g4\stm32g4.dtsi:281 */
		usart3: serial@40004800 {
			compatible = "st,stm32-usart",
			             "st,stm32-uart";   /* in zephyr\dts\arm\st\g4\stm32g4.dtsi:282 */
			reg = < 0x40004800 0x400 >;     /* in zephyr\dts\arm\st\g4\stm32g4.dtsi:283 */
			clocks = < &rcc 0x58 0x40000 >; /* in zephyr\dts\arm\st\g4\stm32g4.dtsi:284 */
			resets = < &rctl 0x712 >;       /* in zephyr\dts\arm\st\g4\stm32g4.dtsi:285 */
			interrupts = < 0x27 0x0 >;      /* in zephyr\dts\arm\st\g4\stm32g4.dtsi:286 */
			status = "disabled";            /* in zephyr\dts\arm\st\g4\stm32g4.dtsi:287 */
		};

		/* node '/soc/serial@40004c00' defined in zephyr\dts\arm\st\g4\stm32g4.dtsi:290 */
		uart4: serial@40004c00 {
			compatible = "st,stm32-uart";   /* in zephyr\dts\arm\st\g4\stm32g4.dtsi:291 */
			reg = < 0x40004c00 0x400 >;     /* in zephyr\dts\arm\st\g4\stm32g4.dtsi:292 */
			clocks = < &rcc 0x58 0x80000 >; /* in zephyr\dts\arm\st\g4\stm32g4.dtsi:293 */
			resets = < &rctl 0x713 >;       /* in zephyr\dts\arm\st\g4\stm32g4.dtsi:294 */
			interrupts = < 0x34 0x0 >;      /* in zephyr\dts\arm\st\g4\stm32g4.dtsi:295 */
			status = "disabled";            /* in zephyr\dts\arm\st\g4\stm32g4.dtsi:296 */
		};

		/* node '/soc/serial@40008000' defined in zephyr\dts\arm\st\g4\stm32g4.dtsi:299 */
		lpuart1: serial@40008000 {
			compatible = "st,stm32-lpuart",
			             "st,stm32-uart";                    /* in zephyr\dts\arm\st\g4\stm32g4.dtsi:300 */
			reg = < 0x40008000 0x400 >;                      /* in zephyr\dts\arm\st\g4\stm32g4.dtsi:301 */
			clocks = < &rcc 0x5c 0x1 >;                      /* in zephyr\dts\arm\st\g4\stm32g4.dtsi:302 */
			resets = < &rctl 0x780 >;                        /* in zephyr\dts\arm\st\g4\stm32g4.dtsi:303 */
			interrupts = < 0x5b 0x0 >;                       /* in zephyr\dts\arm\st\g4\stm32g4.dtsi:304 */
			pinctrl-0 = < &lpuart1_tx_pa2 &lpuart1_rx_pa3 >; /* in zephyr\boards\st\nucleo_g431rb\nucleo_g431rb.dts:111 */
			pinctrl-names = "default";                       /* in zephyr\boards\st\nucleo_g431rb\nucleo_g431rb.dts:112 */
			current-speed = < 0x1c200 >;                     /* in zephyr\boards\st\nucleo_g431rb\nucleo_g431rb.dts:113 */
			status = "okay";                                 /* in zephyr\boards\st\nucleo_g431rb\nucleo_g431rb.dts:114 */
		};

		/* node '/soc/watchdog@40003000' defined in zephyr\dts\arm\st\g4\stm32g4.dtsi:308 */
		iwdg: watchdog@40003000 {
			compatible = "st,stm32-watchdog"; /* in zephyr\dts\arm\st\g4\stm32g4.dtsi:309 */
			reg = < 0x40003000 0x400 >;       /* in zephyr\dts\arm\st\g4\stm32g4.dtsi:310 */
			status = "okay";                  /* in zephyr\boards\st\nucleo_g431rb\nucleo_g431rb.dts:197 */
		};

		/* node '/soc/watchdog@40002c00' defined in zephyr\dts\arm\st\g4\stm32g4.dtsi:314 */
		wwdg: watchdog@40002c00 {
			compatible = "st,stm32-window-watchdog"; /* in zephyr\dts\arm\st\g4\stm32g4.dtsi:315 */
			reg = < 0x40002c00 0x400 >;              /* in zephyr\dts\arm\st\g4\stm32g4.dtsi:316 */
			clocks = < &rcc 0x58 0x800 >;            /* in zephyr\dts\arm\st\g4\stm32g4.dtsi:317 */
			interrupts = < 0x0 0x7 >;                /* in zephyr\dts\arm\st\g4\stm32g4.dtsi:318 */
			status = "disabled";                     /* in zephyr\dts\arm\st\g4\stm32g4.dtsi:319 */
		};

		/* node '/soc/i2c@40005400' defined in zephyr\dts\arm\st\g4\stm32g4.dtsi:322 */
		i2c1: arduino_i2c: i2c@40005400 {
			compatible = "st,stm32-i2c-v2";              /* in zephyr\dts\arm\st\g4\stm32g4.dtsi:323 */
			clock-frequency = < 0x186a0 >;               /* in zephyr\dts\arm\st\g4\stm32g4.dtsi:324 */
			#address-cells = < 0x1 >;                    /* in zephyr\dts\arm\st\g4\stm32g4.dtsi:325 */
			#size-cells = < 0x0 >;                       /* in zephyr\dts\arm\st\g4\stm32g4.dtsi:326 */
			reg = < 0x40005400 0x400 >;                  /* in zephyr\dts\arm\st\g4\stm32g4.dtsi:327 */
			clocks = < &rcc 0x58 0x200000 >;             /* in zephyr\dts\arm\st\g4\stm32g4.dtsi:328 */
			interrupts = < 0x1f 0x0 >,
			             < 0x20 0x0 >;                   /* in zephyr\dts\arm\st\g4\stm32g4.dtsi:329 */
			interrupt-names = "event",
			                  "error";                   /* in zephyr\dts\arm\st\g4\stm32g4.dtsi:330 */
			pinctrl-0 = < &i2c1_scl_pb8 &i2c1_sda_pb9 >; /* in zephyr\boards\st\nucleo_g431rb\nucleo_g431rb.dts:118 */
			pinctrl-names = "default";                   /* in zephyr\boards\st\nucleo_g431rb\nucleo_g431rb.dts:119 */
			status = "okay";                             /* in zephyr\boards\st\nucleo_g431rb\nucleo_g431rb.dts:120 */
			phandle = < 0x1e >;                          /* in zephyr\dts\arm\st\g4\stm32g4.dtsi:703 */
		};

		/* node '/soc/i2c@40005800' defined in zephyr\dts\arm\st\g4\stm32g4.dtsi:334 */
		i2c2: i2c@40005800 {
			compatible = "st,stm32-i2c-v2";  /* in zephyr\dts\arm\st\g4\stm32g4.dtsi:335 */
			clock-frequency = < 0x186a0 >;   /* in zephyr\dts\arm\st\g4\stm32g4.dtsi:336 */
			#address-cells = < 0x1 >;        /* in zephyr\dts\arm\st\g4\stm32g4.dtsi:337 */
			#size-cells = < 0x0 >;           /* in zephyr\dts\arm\st\g4\stm32g4.dtsi:338 */
			reg = < 0x40005800 0x400 >;      /* in zephyr\dts\arm\st\g4\stm32g4.dtsi:339 */
			clocks = < &rcc 0x58 0x400000 >; /* in zephyr\dts\arm\st\g4\stm32g4.dtsi:340 */
			interrupts = < 0x21 0x0 >,
			             < 0x22 0x0 >;       /* in zephyr\dts\arm\st\g4\stm32g4.dtsi:341 */
			interrupt-names = "event",
			                  "error";       /* in zephyr\dts\arm\st\g4\stm32g4.dtsi:342 */
			status = "disabled";             /* in zephyr\dts\arm\st\g4\stm32g4.dtsi:343 */
			phandle = < 0x1f >;              /* in zephyr\dts\arm\st\g4\stm32g4.dtsi:711 */
		};

		/* node '/soc/i2c@40007800' defined in zephyr\dts\arm\st\g4\stm32g4.dtsi:346 */
		i2c3: i2c@40007800 {
			compatible = "st,stm32-i2c-v2";    /* in zephyr\dts\arm\st\g4\stm32g4.dtsi:347 */
			clock-frequency = < 0x186a0 >;     /* in zephyr\dts\arm\st\g4\stm32g4.dtsi:348 */
			#address-cells = < 0x1 >;          /* in zephyr\dts\arm\st\g4\stm32g4.dtsi:349 */
			#size-cells = < 0x0 >;             /* in zephyr\dts\arm\st\g4\stm32g4.dtsi:350 */
			reg = < 0x40007800 0x400 >;        /* in zephyr\dts\arm\st\g4\stm32g4.dtsi:351 */
			clocks = < &rcc 0x58 0x40000000 >; /* in zephyr\dts\arm\st\g4\stm32g4.dtsi:352 */
			interrupts = < 0x5c 0x0 >,
			             < 0x5d 0x0 >;         /* in zephyr\dts\arm\st\g4\stm32g4.dtsi:353 */
			interrupt-names = "event",
			                  "error";         /* in zephyr\dts\arm\st\g4\stm32g4.dtsi:354 */
			status = "disabled";               /* in zephyr\dts\arm\st\g4\stm32g4.dtsi:355 */
			phandle = < 0x20 >;                /* in zephyr\dts\arm\st\g4\stm32g4.dtsi:719 */
		};

		/* node '/soc/spi@40013000' defined in zephyr\dts\arm\st\g4\stm32g4.dtsi:358 */
		spi1: arduino_spi: spi@40013000 {
			compatible = "st,stm32-spi-fifo",
			             "st,stm32-spi";                                 /* in zephyr\dts\arm\st\g4\stm32g4.dtsi:359 */
			#address-cells = < 0x1 >;                                    /* in zephyr\dts\arm\st\g4\stm32g4.dtsi:360 */
			#size-cells = < 0x0 >;                                       /* in zephyr\dts\arm\st\g4\stm32g4.dtsi:361 */
			reg = < 0x40013000 0x400 >;                                  /* in zephyr\dts\arm\st\g4\stm32g4.dtsi:362 */
			interrupts = < 0x23 0x5 >;                                   /* in zephyr\dts\arm\st\g4\stm32g4.dtsi:363 */
			clocks = < &rcc 0x60 0x1000 >;                               /* in zephyr\dts\arm\st\g4\stm32g4.dtsi:364 */
			pinctrl-0 = < &spi1_sck_pa5 &spi1_miso_pa6 &spi1_mosi_pa7 >; /* in zephyr\boards\st\nucleo_g431rb\nucleo_g431rb.dts:124 */
			pinctrl-names = "default";                                   /* in zephyr\boards\st\nucleo_g431rb\nucleo_g431rb.dts:125 */
			cs-gpios = < &gpiob 0x6 0x11 >;                              /* in zephyr\boards\st\nucleo_g431rb\nucleo_g431rb.dts:126 */
			status = "okay";                                             /* in zephyr\boards\st\nucleo_g431rb\nucleo_g431rb.dts:127 */
		};

		/* node '/soc/spi@40003800' defined in zephyr\dts\arm\st\g4\stm32g4.dtsi:368 */
		spi2: spi@40003800 {
			compatible = "st,stm32-spi-fifo",
			             "st,stm32-spi";                                                   /* in zephyr\dts\arm\st\g4\stm32g4.dtsi:369 */
			#address-cells = < 0x1 >;                                                      /* in zephyr\dts\arm\st\g4\stm32g4.dtsi:370 */
			#size-cells = < 0x0 >;                                                         /* in zephyr\dts\arm\st\g4\stm32g4.dtsi:371 */
			reg = < 0x40003800 0x400 >;                                                    /* in zephyr\dts\arm\st\g4\stm32g4.dtsi:372 */
			clocks = < &rcc 0x58 0x4000 >;                                                 /* in zephyr\dts\arm\st\g4\stm32g4.dtsi:373 */
			interrupts = < 0x24 0x5 >;                                                     /* in zephyr\dts\arm\st\g4\stm32g4.dtsi:374 */
			pinctrl-0 = < &spi2_nss_pb12 &spi2_sck_pb13 &spi2_miso_pb14 &spi2_mosi_pb15 >; /* in zephyr\boards\st\nucleo_g431rb\nucleo_g431rb.dts:131 */
			pinctrl-names = "default";                                                     /* in zephyr\boards\st\nucleo_g431rb\nucleo_g431rb.dts:133 */
			status = "okay";                                                               /* in zephyr\boards\st\nucleo_g431rb\nucleo_g431rb.dts:134 */
		};

		/* node '/soc/spi@40003c00' defined in zephyr\dts\arm\st\g4\stm32g4.dtsi:378 */
		spi3: spi@40003c00 {
			compatible = "st,stm32-spi-fifo",
			             "st,stm32-spi";                                                   /* in zephyr\dts\arm\st\g4\stm32g4.dtsi:379 */
			#address-cells = < 0x1 >;                                                      /* in zephyr\dts\arm\st\g4\stm32g4.dtsi:380 */
			#size-cells = < 0x0 >;                                                         /* in zephyr\dts\arm\st\g4\stm32g4.dtsi:381 */
			reg = < 0x40003c00 0x400 >;                                                    /* in zephyr\dts\arm\st\g4\stm32g4.dtsi:382 */
			clocks = < &rcc 0x58 0x8000 >;                                                 /* in zephyr\dts\arm\st\g4\stm32g4.dtsi:383 */
			interrupts = < 0x33 0x5 >;                                                     /* in zephyr\dts\arm\st\g4\stm32g4.dtsi:384 */
			pinctrl-0 = < &spi3_nss_pa15 &spi3_sck_pc10 &spi3_miso_pc11 &spi3_mosi_pc12 >; /* in zephyr\boards\st\nucleo_g431rb\nucleo_g431rb.dts:139 */
			pinctrl-names = "default";                                                     /* in zephyr\boards\st\nucleo_g431rb\nucleo_g431rb.dts:141 */
			status = "okay";                                                               /* in zephyr\boards\st\nucleo_g431rb\nucleo_g431rb.dts:142 */
		};

		/* node '/soc/can@40006400' defined in zephyr\dts\arm\st\g4\stm32g4.dtsi:388 */
		fdcan1: can@40006400 {
			compatible = "st,stm32-fdcan";                         /* in zephyr\dts\arm\st\g4\stm32g4.dtsi:389 */
			reg = < 0x40006400 0x400 >,
			      < 0x4000a400 0x350 >;                            /* in zephyr\dts\arm\st\g4\stm32g4.dtsi:390 */
			reg-names = "m_can",
			            "message_ram";                             /* in zephyr\dts\arm\st\g4\stm32g4.dtsi:391 */
			interrupts = < 0x15 0x0 >,
			             < 0x16 0x0 >;                             /* in zephyr\dts\arm\st\g4\stm32g4.dtsi:392 */
			interrupt-names = "int0",
			                  "int1";                              /* in zephyr\dts\arm\st\g4\stm32g4.dtsi:393 */
			clocks = < &rcc 0x58 0x2000000 >;                      /* in zephyr\dts\arm\st\g4\stm32g4.dtsi:394 */
			bosch,mram-cfg = < 0x0 0x1c 0x8 0x3 0x3 0x0 0x3 0x3 >; /* in zephyr\dts\arm\st\g4\stm32g4.dtsi:395 */
			status = "disabled";                                   /* in zephyr\dts\arm\st\g4\stm32g4.dtsi:396 */
		};

		/* node '/soc/timers@40007c00' defined in zephyr\dts\arm\st\g4\stm32g4.dtsi:399 */
		lptim1: stm32_lp_tick_source: timers@40007c00 {
			compatible = "st,stm32-lptim";     /* in zephyr\dts\arm\st\g4\stm32g4.dtsi:400 */
			#address-cells = < 0x1 >;          /* in zephyr\dts\arm\st\g4\stm32g4.dtsi:402 */
			#size-cells = < 0x0 >;             /* in zephyr\dts\arm\st\g4\stm32g4.dtsi:403 */
			reg = < 0x40007c00 0x400 >;        /* in zephyr\dts\arm\st\g4\stm32g4.dtsi:404 */
			interrupts = < 0x31 0x1 >;         /* in zephyr\dts\arm\st\g4\stm32g4.dtsi:405 */
			interrupt-names = "wakeup";        /* in zephyr\dts\arm\st\g4\stm32g4.dtsi:406 */
			clocks = < &rcc 0x58 0x80000000 >,
			         < &rcc 0x2 0x18d20088 >;  /* in zephyr\boards\st\nucleo_g431rb\nucleo_g431rb.dts:156 */
			status = "okay";                   /* in zephyr\boards\st\nucleo_g431rb\nucleo_g431rb.dts:158 */
		};

		/* node '/soc/timers@40012c00' defined in zephyr\dts\arm\st\g4\stm32g4.dtsi:410 */
		timers1: timers@40012c00 {
			compatible = "st,stm32-timers"; /* in zephyr\dts\arm\st\g4\stm32g4.dtsi:411 */
			reg = < 0x40012c00 0x400 >;     /* in zephyr\dts\arm\st\g4\stm32g4.dtsi:412 */
			clocks = < &rcc 0x60 0x800 >;   /* in zephyr\dts\arm\st\g4\stm32g4.dtsi:413 */
			resets = < &rctl 0x80b >;       /* in zephyr\dts\arm\st\g4\stm32g4.dtsi:414 */
			interrupts = < 0x18 0x0 >,
			             < 0x19 0x0 >,
			             < 0x1a 0x0 >,
			             < 0x1b 0x0 >;      /* in zephyr\dts\arm\st\g4\stm32g4.dtsi:415 */
			interrupt-names = "brk",
			                  "up",
			                  "trgcom",
			                  "cc";         /* in zephyr\dts\arm\st\g4\stm32g4.dtsi:416 */
			st,prescaler = < 0x0 >;         /* in zephyr\dts\arm\st\g4\stm32g4.dtsi:417 */
			status = "disabled";            /* in zephyr\dts\arm\st\g4\stm32g4.dtsi:418 */

			/* node '/soc/timers@40012c00/pwm' defined in zephyr\dts\arm\st\g4\stm32g4.dtsi:420 */
			pwm {
				compatible = "st,stm32-pwm"; /* in zephyr\dts\arm\st\g4\stm32g4.dtsi:421 */
				status = "disabled";         /* in zephyr\dts\arm\st\g4\stm32g4.dtsi:422 */
				#pwm-cells = < 0x3 >;        /* in zephyr\dts\arm\st\g4\stm32g4.dtsi:423 */
			};
		};

		/* node '/soc/timers@40000000' defined in zephyr\dts\arm\st\g4\stm32g4.dtsi:427 */
		timers2: timers@40000000 {
			compatible = "st,stm32-timers"; /* in zephyr\dts\arm\st\g4\stm32g4.dtsi:428 */
			reg = < 0x40000000 0x400 >;     /* in zephyr\dts\arm\st\g4\stm32g4.dtsi:429 */
			clocks = < &rcc 0x58 0x1 >;     /* in zephyr\dts\arm\st\g4\stm32g4.dtsi:430 */
			resets = < &rctl 0x700 >;       /* in zephyr\dts\arm\st\g4\stm32g4.dtsi:431 */
			interrupts = < 0x1c 0x0 >;      /* in zephyr\dts\arm\st\g4\stm32g4.dtsi:432 */
			interrupt-names = "global";     /* in zephyr\dts\arm\st\g4\stm32g4.dtsi:433 */
			st,prescaler = < 0x0 >;         /* in zephyr\dts\arm\st\g4\stm32g4.dtsi:434 */
			status = "okay";                /* in zephyr\boards\st\nucleo_g431rb\nucleo_g431rb.dts:146 */

			/* node '/soc/timers@40000000/counter' defined in zephyr\dts\arm\st\g4\stm32g4.dtsi:437 */
			counter {
				compatible = "st,stm32-counter"; /* in zephyr\dts\arm\st\g4\stm32g4.dtsi:438 */
				status = "disabled";             /* in zephyr\dts\arm\st\g4\stm32g4.dtsi:439 */
			};

			/* node '/soc/timers@40000000/pwm' defined in zephyr\dts\arm\st\g4\stm32g4.dtsi:442 */
			pwm2: pwm {
				compatible = "st,stm32-pwm";   /* in zephyr\dts\arm\st\g4\stm32g4.dtsi:443 */
				#pwm-cells = < 0x3 >;          /* in zephyr\dts\arm\st\g4\stm32g4.dtsi:445 */
				status = "okay";               /* in zephyr\boards\st\nucleo_g431rb\nucleo_g431rb.dts:149 */
				pinctrl-0 = < &tim2_ch1_pa5 >; /* in zephyr\boards\st\nucleo_g431rb\nucleo_g431rb.dts:150 */
				pinctrl-names = "default";     /* in zephyr\boards\st\nucleo_g431rb\nucleo_g431rb.dts:151 */
				phandle = < 0x25 >;            /* in zephyr\boards\st\nucleo_g431rb\nucleo_g431rb.dts:39 */
			};
		};

		/* node '/soc/timers@40000400' defined in zephyr\dts\arm\st\g4\stm32g4.dtsi:449 */
		timers3: timers@40000400 {
			compatible = "st,stm32-timers"; /* in zephyr\dts\arm\st\g4\stm32g4.dtsi:450 */
			reg = < 0x40000400 0x400 >;     /* in zephyr\dts\arm\st\g4\stm32g4.dtsi:451 */
			clocks = < &rcc 0x58 0x2 >;     /* in zephyr\dts\arm\st\g4\stm32g4.dtsi:452 */
			resets = < &rctl 0x701 >;       /* in zephyr\dts\arm\st\g4\stm32g4.dtsi:453 */
			interrupts = < 0x1d 0x0 >;      /* in zephyr\dts\arm\st\g4\stm32g4.dtsi:454 */
			interrupt-names = "global";     /* in zephyr\dts\arm\st\g4\stm32g4.dtsi:455 */
			st,prescaler = < 0x0 >;         /* in zephyr\dts\arm\st\g4\stm32g4.dtsi:456 */
			status = "disabled";            /* in zephyr\dts\arm\st\g4\stm32g4.dtsi:457 */

			/* node '/soc/timers@40000400/counter' defined in zephyr\dts\arm\st\g4\stm32g4.dtsi:459 */
			counter {
				compatible = "st,stm32-counter"; /* in zephyr\dts\arm\st\g4\stm32g4.dtsi:460 */
				status = "disabled";             /* in zephyr\dts\arm\st\g4\stm32g4.dtsi:461 */
			};

			/* node '/soc/timers@40000400/pwm' defined in zephyr\dts\arm\st\g4\stm32g4.dtsi:464 */
			pwm {
				compatible = "st,stm32-pwm"; /* in zephyr\dts\arm\st\g4\stm32g4.dtsi:465 */
				status = "disabled";         /* in zephyr\dts\arm\st\g4\stm32g4.dtsi:466 */
				#pwm-cells = < 0x3 >;        /* in zephyr\dts\arm\st\g4\stm32g4.dtsi:467 */
			};
		};

		/* node '/soc/timers@40000800' defined in zephyr\dts\arm\st\g4\stm32g4.dtsi:471 */
		timers4: timers@40000800 {
			compatible = "st,stm32-timers"; /* in zephyr\dts\arm\st\g4\stm32g4.dtsi:472 */
			reg = < 0x40000800 0x400 >;     /* in zephyr\dts\arm\st\g4\stm32g4.dtsi:473 */
			clocks = < &rcc 0x58 0x4 >;     /* in zephyr\dts\arm\st\g4\stm32g4.dtsi:474 */
			resets = < &rctl 0x702 >;       /* in zephyr\dts\arm\st\g4\stm32g4.dtsi:475 */
			interrupts = < 0x1e 0x0 >;      /* in zephyr\dts\arm\st\g4\stm32g4.dtsi:476 */
			interrupt-names = "global";     /* in zephyr\dts\arm\st\g4\stm32g4.dtsi:477 */
			st,prescaler = < 0x0 >;         /* in zephyr\dts\arm\st\g4\stm32g4.dtsi:478 */
			status = "disabled";            /* in zephyr\dts\arm\st\g4\stm32g4.dtsi:479 */

			/* node '/soc/timers@40000800/counter' defined in zephyr\dts\arm\st\g4\stm32g4.dtsi:481 */
			counter {
				compatible = "st,stm32-counter"; /* in zephyr\dts\arm\st\g4\stm32g4.dtsi:482 */
				status = "disabled";             /* in zephyr\dts\arm\st\g4\stm32g4.dtsi:483 */
			};

			/* node '/soc/timers@40000800/pwm' defined in zephyr\dts\arm\st\g4\stm32g4.dtsi:486 */
			pwm {
				compatible = "st,stm32-pwm"; /* in zephyr\dts\arm\st\g4\stm32g4.dtsi:487 */
				status = "disabled";         /* in zephyr\dts\arm\st\g4\stm32g4.dtsi:488 */
				#pwm-cells = < 0x3 >;        /* in zephyr\dts\arm\st\g4\stm32g4.dtsi:489 */
			};
		};

		/* node '/soc/timers@40001000' defined in zephyr\dts\arm\st\g4\stm32g4.dtsi:493 */
		timers6: timers@40001000 {
			compatible = "st,stm32-timers"; /* in zephyr\dts\arm\st\g4\stm32g4.dtsi:494 */
			reg = < 0x40001000 0x400 >;     /* in zephyr\dts\arm\st\g4\stm32g4.dtsi:495 */
			clocks = < &rcc 0x58 0x10 >;    /* in zephyr\dts\arm\st\g4\stm32g4.dtsi:496 */
			resets = < &rctl 0x704 >;       /* in zephyr\dts\arm\st\g4\stm32g4.dtsi:497 */
			interrupts = < 0x36 0x0 >;      /* in zephyr\dts\arm\st\g4\stm32g4.dtsi:498 */
			interrupt-names = "global";     /* in zephyr\dts\arm\st\g4\stm32g4.dtsi:499 */
			st,prescaler = < 0x0 >;         /* in zephyr\dts\arm\st\g4\stm32g4.dtsi:500 */
			status = "disabled";            /* in zephyr\dts\arm\st\g4\stm32g4.dtsi:501 */
		};

		/* node '/soc/timers@40001400' defined in zephyr\dts\arm\st\g4\stm32g4.dtsi:504 */
		timers7: timers@40001400 {
			compatible = "st,stm32-timers"; /* in zephyr\dts\arm\st\g4\stm32g4.dtsi:505 */
			reg = < 0x40001400 0x400 >;     /* in zephyr\dts\arm\st\g4\stm32g4.dtsi:506 */
			clocks = < &rcc 0x58 0x20 >;    /* in zephyr\dts\arm\st\g4\stm32g4.dtsi:507 */
			resets = < &rctl 0x705 >;       /* in zephyr\dts\arm\st\g4\stm32g4.dtsi:508 */
			interrupts = < 0x37 0x0 >;      /* in zephyr\dts\arm\st\g4\stm32g4.dtsi:509 */
			interrupt-names = "global";     /* in zephyr\dts\arm\st\g4\stm32g4.dtsi:510 */
			st,prescaler = < 0x0 >;         /* in zephyr\dts\arm\st\g4\stm32g4.dtsi:511 */
			status = "disabled";            /* in zephyr\dts\arm\st\g4\stm32g4.dtsi:512 */
		};

		/* node '/soc/timers@40013400' defined in zephyr\dts\arm\st\g4\stm32g4.dtsi:515 */
		timers8: timers@40013400 {
			compatible = "st,stm32-timers"; /* in zephyr\dts\arm\st\g4\stm32g4.dtsi:516 */
			reg = < 0x40013400 0x400 >;     /* in zephyr\dts\arm\st\g4\stm32g4.dtsi:517 */
			clocks = < &rcc 0x60 0x2000 >;  /* in zephyr\dts\arm\st\g4\stm32g4.dtsi:518 */
			resets = < &rctl 0x80d >;       /* in zephyr\dts\arm\st\g4\stm32g4.dtsi:519 */
			interrupts = < 0x2b 0x0 >,
			             < 0x2c 0x0 >,
			             < 0x2d 0x0 >,
			             < 0x2e 0x0 >;      /* in zephyr\dts\arm\st\g4\stm32g4.dtsi:520 */
			interrupt-names = "brk",
			                  "up",
			                  "trgcom",
			                  "cc";         /* in zephyr\dts\arm\st\g4\stm32g4.dtsi:521 */
			st,prescaler = < 0x0 >;         /* in zephyr\dts\arm\st\g4\stm32g4.dtsi:522 */
			status = "disabled";            /* in zephyr\dts\arm\st\g4\stm32g4.dtsi:523 */

			/* node '/soc/timers@40013400/pwm' defined in zephyr\dts\arm\st\g4\stm32g4.dtsi:525 */
			pwm {
				compatible = "st,stm32-pwm"; /* in zephyr\dts\arm\st\g4\stm32g4.dtsi:526 */
				status = "disabled";         /* in zephyr\dts\arm\st\g4\stm32g4.dtsi:527 */
				#pwm-cells = < 0x3 >;        /* in zephyr\dts\arm\st\g4\stm32g4.dtsi:528 */
			};
		};

		/* node '/soc/timers@40014000' defined in zephyr\dts\arm\st\g4\stm32g4.dtsi:532 */
		timers15: timers@40014000 {
			compatible = "st,stm32-timers"; /* in zephyr\dts\arm\st\g4\stm32g4.dtsi:533 */
			reg = < 0x40014000 0x400 >;     /* in zephyr\dts\arm\st\g4\stm32g4.dtsi:534 */
			clocks = < &rcc 0x60 0x10000 >; /* in zephyr\dts\arm\st\g4\stm32g4.dtsi:535 */
			resets = < &rctl 0x810 >;       /* in zephyr\dts\arm\st\g4\stm32g4.dtsi:536 */
			interrupts = < 0x18 0x0 >;      /* in zephyr\dts\arm\st\g4\stm32g4.dtsi:537 */
			interrupt-names = "global";     /* in zephyr\dts\arm\st\g4\stm32g4.dtsi:538 */
			st,prescaler = < 0x0 >;         /* in zephyr\dts\arm\st\g4\stm32g4.dtsi:539 */
			status = "disabled";            /* in zephyr\dts\arm\st\g4\stm32g4.dtsi:540 */

			/* node '/soc/timers@40014000/pwm' defined in zephyr\dts\arm\st\g4\stm32g4.dtsi:542 */
			pwm {
				compatible = "st,stm32-pwm"; /* in zephyr\dts\arm\st\g4\stm32g4.dtsi:543 */
				status = "disabled";         /* in zephyr\dts\arm\st\g4\stm32g4.dtsi:544 */
				#pwm-cells = < 0x3 >;        /* in zephyr\dts\arm\st\g4\stm32g4.dtsi:545 */
			};

			/* node '/soc/timers@40014000/counter' defined in zephyr\dts\arm\st\g4\stm32g4.dtsi:548 */
			counter {
				compatible = "st,stm32-counter"; /* in zephyr\dts\arm\st\g4\stm32g4.dtsi:549 */
				status = "disabled";             /* in zephyr\dts\arm\st\g4\stm32g4.dtsi:550 */
			};
		};

		/* node '/soc/timers@40014400' defined in zephyr\dts\arm\st\g4\stm32g4.dtsi:554 */
		timers16: timers@40014400 {
			compatible = "st,stm32-timers"; /* in zephyr\dts\arm\st\g4\stm32g4.dtsi:555 */
			reg = < 0x40014400 0x400 >;     /* in zephyr\dts\arm\st\g4\stm32g4.dtsi:556 */
			clocks = < &rcc 0x60 0x20000 >; /* in zephyr\dts\arm\st\g4\stm32g4.dtsi:557 */
			resets = < &rctl 0x811 >;       /* in zephyr\dts\arm\st\g4\stm32g4.dtsi:558 */
			interrupts = < 0x19 0x0 >;      /* in zephyr\dts\arm\st\g4\stm32g4.dtsi:559 */
			interrupt-names = "global";     /* in zephyr\dts\arm\st\g4\stm32g4.dtsi:560 */
			st,prescaler = < 0x0 >;         /* in zephyr\dts\arm\st\g4\stm32g4.dtsi:561 */
			status = "disabled";            /* in zephyr\dts\arm\st\g4\stm32g4.dtsi:562 */

			/* node '/soc/timers@40014400/pwm' defined in zephyr\dts\arm\st\g4\stm32g4.dtsi:564 */
			pwm {
				compatible = "st,stm32-pwm"; /* in zephyr\dts\arm\st\g4\stm32g4.dtsi:565 */
				status = "disabled";         /* in zephyr\dts\arm\st\g4\stm32g4.dtsi:566 */
				#pwm-cells = < 0x3 >;        /* in zephyr\dts\arm\st\g4\stm32g4.dtsi:567 */
			};

			/* node '/soc/timers@40014400/counter' defined in zephyr\dts\arm\st\g4\stm32g4.dtsi:570 */
			counter {
				compatible = "st,stm32-counter"; /* in zephyr\dts\arm\st\g4\stm32g4.dtsi:571 */
				status = "disabled";             /* in zephyr\dts\arm\st\g4\stm32g4.dtsi:572 */
			};
		};

		/* node '/soc/timers@40014800' defined in zephyr\dts\arm\st\g4\stm32g4.dtsi:576 */
		timers17: timers@40014800 {
			compatible = "st,stm32-timers"; /* in zephyr\dts\arm\st\g4\stm32g4.dtsi:577 */
			reg = < 0x40014800 0x400 >;     /* in zephyr\dts\arm\st\g4\stm32g4.dtsi:578 */
			clocks = < &rcc 0x60 0x40000 >; /* in zephyr\dts\arm\st\g4\stm32g4.dtsi:579 */
			resets = < &rctl 0x812 >;       /* in zephyr\dts\arm\st\g4\stm32g4.dtsi:580 */
			interrupts = < 0x1a 0x0 >;      /* in zephyr\dts\arm\st\g4\stm32g4.dtsi:581 */
			interrupt-names = "global";     /* in zephyr\dts\arm\st\g4\stm32g4.dtsi:582 */
			st,prescaler = < 0x0 >;         /* in zephyr\dts\arm\st\g4\stm32g4.dtsi:583 */
			status = "disabled";            /* in zephyr\dts\arm\st\g4\stm32g4.dtsi:584 */

			/* node '/soc/timers@40014800/pwm' defined in zephyr\dts\arm\st\g4\stm32g4.dtsi:586 */
			pwm {
				compatible = "st,stm32-pwm"; /* in zephyr\dts\arm\st\g4\stm32g4.dtsi:587 */
				status = "disabled";         /* in zephyr\dts\arm\st\g4\stm32g4.dtsi:588 */
				#pwm-cells = < 0x3 >;        /* in zephyr\dts\arm\st\g4\stm32g4.dtsi:589 */
			};

			/* node '/soc/timers@40014800/counter' defined in zephyr\dts\arm\st\g4\stm32g4.dtsi:592 */
			counter {
				compatible = "st,stm32-counter"; /* in zephyr\dts\arm\st\g4\stm32g4.dtsi:593 */
				status = "disabled";             /* in zephyr\dts\arm\st\g4\stm32g4.dtsi:594 */
			};
		};

		/* node '/soc/rtc@40002800' defined in zephyr\dts\arm\st\g4\stm32g4.dtsi:598 */
		rtc: rtc@40002800 {
			compatible = "st,stm32-rtc";      /* in zephyr\dts\arm\st\g4\stm32g4.dtsi:599 */
			reg = < 0x40002800 0x400 >;       /* in zephyr\dts\arm\st\g4\stm32g4.dtsi:600 */
			interrupts = < 0x29 0x0 >;        /* in zephyr\dts\arm\st\g4\stm32g4.dtsi:601 */
			prescaler = < 0x8000 >;           /* in zephyr\dts\arm\st\g4\stm32g4.dtsi:603 */
			alarms-count = < 0x2 >;           /* in zephyr\dts\arm\st\g4\stm32g4.dtsi:604 */
			alrm-exti-line = < 0x11 >;        /* in zephyr\dts\arm\st\g4\stm32g4.dtsi:605 */
			clocks = < &rcc 0x58 0x400 >,
			         < &rcc 0x3 0x10c80090 >; /* in zephyr\boards\st\nucleo_g431rb\nucleo_g431rb.dts:162 */
			status = "okay";                  /* in zephyr\boards\st\nucleo_g431rb\nucleo_g431rb.dts:164 */
		};

		/* node '/soc/rng@50060800' defined in zephyr\dts\arm\st\g4\stm32g4.dtsi:609 */
		rng: rng@50060800 {
			compatible = "st,stm32-rng";      /* in zephyr\dts\arm\st\g4\stm32g4.dtsi:610 */
			reg = < 0x50060800 0x400 >;       /* in zephyr\dts\arm\st\g4\stm32g4.dtsi:611 */
			interrupts = < 0x5a 0x0 >;        /* in zephyr\dts\arm\st\g4\stm32g4.dtsi:612 */
			clocks = < &rcc 0x4c 0x4000000 >,
			         < &rcc 0x5 0xda0088 >;   /* in zephyr\boards\st\nucleo_g431rb\nucleo_g431rb.dts:98 */
			status = "okay";                  /* in zephyr\boards\st\nucleo_g431rb\nucleo_g431rb.dts:100 */
		};

		/* node '/soc/usb@40005c00' defined in zephyr\dts\arm\st\g4\stm32g4.dtsi:617 */
		usb: usb@40005c00 {
			compatible = "st,stm32-usb";     /* in zephyr\dts\arm\st\g4\stm32g4.dtsi:618 */
			reg = < 0x40005c00 0x400 >;      /* in zephyr\dts\arm\st\g4\stm32g4.dtsi:619 */
			interrupts = < 0x14 0x0 >,
			             < 0x13 0x0 >;       /* in zephyr\dts\arm\st\g4\stm32g4.dtsi:620 */
			interrupt-names = "usb",
			                  "usbhp";       /* in zephyr\dts\arm\st\g4\stm32g4.dtsi:621 */
			num-bidir-endpoints = < 0x8 >;   /* in zephyr\dts\arm\st\g4\stm32g4.dtsi:622 */
			ram-size = < 0x400 >;            /* in zephyr\dts\arm\st\g4\stm32g4.dtsi:623 */
			maximum-speed = "full-speed";    /* in zephyr\dts\arm\st\g4\stm32g4.dtsi:624 */
			phys = < &usb_fs_phy >;          /* in zephyr\dts\arm\st\g4\stm32g4.dtsi:625 */
			clocks = < &rcc 0x58 0x800000 >,
			         < &rcc 0x5 0xda0088 >;  /* in zephyr\dts\arm\st\g4\stm32g4.dtsi:626 */
			status = "disabled";             /* in zephyr\dts\arm\st\g4\stm32g4.dtsi:628 */
		};

		/* node '/soc/dma@40020000' defined in zephyr\dts\arm\st\g4\stm32g4.dtsi:631 */
		dma1: dma@40020000 {
			compatible = "st,stm32-dma-v2";                                    /* in zephyr\dts\arm\st\g4\stm32g4.dtsi:632 */
			#dma-cells = < 0x3 >;                                              /* in zephyr\dts\arm\st\g4\stm32g4.dtsi:633 */
			reg = < 0x40020000 0x400 >;                                        /* in zephyr\dts\arm\st\g4\stm32g4.dtsi:634 */
			clocks = < &rcc 0x48 0x1 >;                                        /* in zephyr\dts\arm\st\g4\stm32g4.dtsi:635 */
			dma-offset = < 0x0 >;                                              /* in zephyr\dts\arm\st\g4\stm32g4.dtsi:636 */
			status = "disabled";                                               /* in zephyr\dts\arm\st\g4\stm32g4.dtsi:637 */
			interrupts = < 0xb 0x0 0xc 0x0 0xd 0x0 0xe 0x0 0xf 0x0 0x10 0x0 >; /* in zephyr\dts\arm\st\g4\stm32g431.dtsi:14 */
			dma-requests = < 0x6 >;                                            /* in zephyr\dts\arm\st\g4\stm32g431.dtsi:15 */
		};

		/* node '/soc/dma@40020400' defined in zephyr\dts\arm\st\g4\stm32g4.dtsi:640 */
		dma2: dma@40020400 {
			compatible = "st,stm32-dma-v2";                                         /* in zephyr\dts\arm\st\g4\stm32g4.dtsi:641 */
			#dma-cells = < 0x3 >;                                                   /* in zephyr\dts\arm\st\g4\stm32g4.dtsi:642 */
			reg = < 0x40020400 0x400 >;                                             /* in zephyr\dts\arm\st\g4\stm32g4.dtsi:643 */
			clocks = < &rcc 0x48 0x2 >;                                             /* in zephyr\dts\arm\st\g4\stm32g4.dtsi:644 */
			status = "disabled";                                                    /* in zephyr\dts\arm\st\g4\stm32g4.dtsi:645 */
			interrupts = < 0x38 0x0 0x39 0x0 0x3a 0x0 0x3b 0x0 0x3c 0x0 0x61 0x0 >; /* in zephyr\dts\arm\st\g4\stm32g431.dtsi:19 */
			dma-requests = < 0x6 >;                                                 /* in zephyr\dts\arm\st\g4\stm32g431.dtsi:20 */
			dma-offset = < 0x6 >;                                                   /* in zephyr\dts\arm\st\g4\stm32g431.dtsi:21 */
		};

		/* node '/soc/dmamux@40020800' defined in zephyr\dts\arm\st\g4\stm32g4.dtsi:648 */
		dmamux1: dmamux@40020800 {
			compatible = "st,stm32-dmamux"; /* in zephyr\dts\arm\st\g4\stm32g4.dtsi:649 */
			#dma-cells = < 0x3 >;           /* in zephyr\dts\arm\st\g4\stm32g4.dtsi:650 */
			reg = < 0x40020800 0x400 >;     /* in zephyr\dts\arm\st\g4\stm32g4.dtsi:651 */
			interrupts = < 0x5e 0x0 >;      /* in zephyr\dts\arm\st\g4\stm32g4.dtsi:652 */
			clocks = < &rcc 0x48 0x4 >;     /* in zephyr\dts\arm\st\g4\stm32g4.dtsi:653 */
			dma-generators = < 0x4 >;       /* in zephyr\dts\arm\st\g4\stm32g4.dtsi:654 */
			dma-requests = < 0x6f >;        /* in zephyr\dts\arm\st\g4\stm32g4.dtsi:655 */
			status = "disabled";            /* in zephyr\dts\arm\st\g4\stm32g4.dtsi:656 */
			dma-channels = < 0xc >;         /* in zephyr\dts\arm\st\g4\stm32g431.dtsi:25 */
		};

		/* node '/soc/ucpd@4000a000' defined in zephyr\dts\arm\st\g4\stm32g4.dtsi:659 */
		ucpd1: ucpd@4000a000 {
			compatible = "st,stm32-ucpd"; /* in zephyr\dts\arm\st\g4\stm32g4.dtsi:660 */
			reg = < 0x4000a000 0x400 >;   /* in zephyr\dts\arm\st\g4\stm32g4.dtsi:661 */
			clocks = < &rcc 0x58 0x10 >;  /* in zephyr\dts\arm\st\g4\stm32g4.dtsi:662 */
			interrupts = < 0x3f 0x0 >;    /* in zephyr\dts\arm\st\g4\stm32g4.dtsi:663 */
			status = "disabled";          /* in zephyr\dts\arm\st\g4\stm32g4.dtsi:664 */
		};
	};

	/* node '/cpus' defined in zephyr\dts\arm\st\g4\stm32g4.dtsi:28 */
	cpus {
		#address-cells = < 0x1 >; /* in zephyr\dts\arm\st\g4\stm32g4.dtsi:29 */
		#size-cells = < 0x0 >;    /* in zephyr\dts\arm\st\g4\stm32g4.dtsi:30 */

		/* node '/cpus/cpu@0' defined in zephyr\dts\arm\st\g4\stm32g4.dtsi:32 */
		cpu0: cpu@0 {
			device_type = "cpu";                  /* in zephyr\dts\arm\st\g4\stm32g4.dtsi:33 */
			compatible = "arm,cortex-m4f";        /* in zephyr\dts\arm\st\g4\stm32g4.dtsi:34 */
			reg = < 0x0 >;                        /* in zephyr\dts\arm\st\g4\stm32g4.dtsi:35 */
			cpu-power-states = < &stop0 &stop1 >; /* in zephyr\dts\arm\st\g4\stm32g4.dtsi:36 */
		};

		/* node '/cpus/power-states' defined in zephyr\dts\arm\st\g4\stm32g4.dtsi:39 */
		power-states {

			/* node '/cpus/power-states/state0' defined in zephyr\dts\arm\st\g4\stm32g4.dtsi:40 */
			stop0: state0 {
				compatible = "zephyr,power-state";    /* in zephyr\dts\arm\st\g4\stm32g4.dtsi:41 */
				power-state-name = "suspend-to-idle"; /* in zephyr\dts\arm\st\g4\stm32g4.dtsi:42 */
				substate-id = < 0x1 >;                /* in zephyr\dts\arm\st\g4\stm32g4.dtsi:43 */
				min-residency-us = < 0x14 >;          /* in zephyr\dts\arm\st\g4\stm32g4.dtsi:44 */
				phandle = < 0x1a >;                   /* in zephyr\dts\arm\st\g4\stm32g4.dtsi:36 */
			};

			/* node '/cpus/power-states/state1' defined in zephyr\dts\arm\st\g4\stm32g4.dtsi:46 */
			stop1: state1 {
				compatible = "zephyr,power-state";    /* in zephyr\dts\arm\st\g4\stm32g4.dtsi:47 */
				power-state-name = "suspend-to-idle"; /* in zephyr\dts\arm\st\g4\stm32g4.dtsi:48 */
				substate-id = < 0x2 >;                /* in zephyr\dts\arm\st\g4\stm32g4.dtsi:49 */
				min-residency-us = < 0x64 >;          /* in zephyr\dts\arm\st\g4\stm32g4.dtsi:50 */
				phandle = < 0x1b >;                   /* in zephyr\dts\arm\st\g4\stm32g4.dtsi:36 */
			};
		};
	};

	/* node '/memory@20000000' defined in zephyr\dts\arm\st\g4\stm32g4.dtsi:55 */
	sram0: memory@20000000 {
		compatible = "mmio-sram";    /* in zephyr\dts\arm\st\g4\stm32g4.dtsi:56 */
		reg = < 0x20000000 0x8000 >; /* in zephyr\dts\arm\st\g4\stm32g431Xb.dtsi:11 */
	};

	/* node '/clocks' defined in zephyr\dts\arm\st\g4\stm32g4.dtsi:59 */
	clocks {

		/* node '/clocks/clk-hse' defined in zephyr\dts\arm\st\g4\stm32g4.dtsi:60 */
		clk_hse: clk-hse {
			#clock-cells = < 0x0 >;            /* in zephyr\dts\arm\st\g4\stm32g4.dtsi:61 */
			compatible = "st,stm32-hse-clock"; /* in zephyr\dts\arm\st\g4\stm32g4.dtsi:62 */
			clock-frequency = < 0x16e3600 >;   /* in zephyr\boards\st\nucleo_g431rb\nucleo_g431rb.dts:75 */
			status = "okay";                   /* in zephyr\boards\st\nucleo_g431rb\nucleo_g431rb.dts:76 */
			phandle = < 0x1c >;                /* in zephyr\boards\st\nucleo_g431rb\nucleo_g431rb.dts:85 */
		};

		/* node '/clocks/clk-hsi' defined in zephyr\dts\arm\st\g4\stm32g4.dtsi:66 */
		clk_hsi: clk-hsi {
			#clock-cells = < 0x0 >;         /* in zephyr\dts\arm\st\g4\stm32g4.dtsi:67 */
			compatible = "fixed-clock";     /* in zephyr\dts\arm\st\g4\stm32g4.dtsi:68 */
			clock-frequency = < 0xf42400 >; /* in zephyr\dts\arm\st\g4\stm32g4.dtsi:69 */
			status = "disabled";            /* in zephyr\dts\arm\st\g4\stm32g4.dtsi:70 */
		};

		/* node '/clocks/clk-hsi48' defined in zephyr\dts\arm\st\g4\stm32g4.dtsi:73 */
		clk_hsi48: clk-hsi48 {
			#clock-cells = < 0x0 >;          /* in zephyr\dts\arm\st\g4\stm32g4.dtsi:74 */
			compatible = "fixed-clock";      /* in zephyr\dts\arm\st\g4\stm32g4.dtsi:75 */
			clock-frequency = < 0x2dc6c00 >; /* in zephyr\dts\arm\st\g4\stm32g4.dtsi:76 */
			status = "okay";                 /* in zephyr\boards\st\nucleo_g431rb\nucleo_g431rb.dts:71 */
		};

		/* node '/clocks/clk-lse' defined in zephyr\dts\arm\st\g4\stm32g4.dtsi:80 */
		clk_lse: clk-lse {
			#clock-cells = < 0x0 >;            /* in zephyr\dts\arm\st\g4\stm32g4.dtsi:81 */
			compatible = "st,stm32-lse-clock"; /* in zephyr\dts\arm\st\g4\stm32g4.dtsi:82 */
			clock-frequency = < 0x8000 >;      /* in zephyr\dts\arm\st\g4\stm32g4.dtsi:83 */
			driving-capability = < 0x0 >;      /* in zephyr\dts\arm\st\g4\stm32g4.dtsi:84 */
			status = "okay";                   /* in zephyr\boards\st\nucleo_g431rb\nucleo_g431rb.dts:67 */
		};

		/* node '/clocks/clk-lsi' defined in zephyr\dts\arm\st\g4\stm32g4.dtsi:88 */
		clk_lsi: clk-lsi {
			#clock-cells = < 0x0 >;       /* in zephyr\dts\arm\st\g4\stm32g4.dtsi:89 */
			compatible = "fixed-clock";   /* in zephyr\dts\arm\st\g4\stm32g4.dtsi:90 */
			clock-frequency = < 0x7d00 >; /* in zephyr\dts\arm\st\g4\stm32g4.dtsi:91 */
			status = "okay";              /* in zephyr\boards\st\nucleo_g431rb\nucleo_g431rb.dts:63 */
		};

		/* node '/clocks/pll' defined in zephyr\dts\arm\st\g4\stm32g4.dtsi:95 */
		pll: pll {
			#clock-cells = < 0x0 >;              /* in zephyr\dts\arm\st\g4\stm32g4.dtsi:96 */
			compatible = "st,stm32g4-pll-clock"; /* in zephyr\dts\arm\st\g4\stm32g4.dtsi:97 */
			div-m = < 0x6 >;                     /* in zephyr\boards\st\nucleo_g431rb\nucleo_g431rb.dts:80 */
			mul-n = < 0x55 >;                    /* in zephyr\boards\st\nucleo_g431rb\nucleo_g431rb.dts:81 */
			div-p = < 0x7 >;                     /* in zephyr\boards\st\nucleo_g431rb\nucleo_g431rb.dts:82 */
			div-q = < 0x2 >;                     /* in zephyr\boards\st\nucleo_g431rb\nucleo_g431rb.dts:83 */
			div-r = < 0x2 >;                     /* in zephyr\boards\st\nucleo_g431rb\nucleo_g431rb.dts:84 */
			clocks = < &clk_hse >;               /* in zephyr\boards\st\nucleo_g431rb\nucleo_g431rb.dts:85 */
			status = "okay";                     /* in zephyr\boards\st\nucleo_g431rb\nucleo_g431rb.dts:86 */
			phandle = < 0x4 >;                   /* in zephyr\boards\st\nucleo_g431rb\nucleo_g431rb.dts:90 */
		};
	};

	/* node '/dietemp' defined in zephyr\dts\arm\st\g4\stm32g4.dtsi:668 */
	die_temp: dietemp {
		compatible = "st,stm32-temp-cal"; /* in zephyr\dts\arm\st\g4\stm32g4.dtsi:669 */
		ts-cal1-addr = < 0x1fff75a8 >;    /* in zephyr\dts\arm\st\g4\stm32g4.dtsi:670 */
		ts-cal2-addr = < 0x1fff75ca >;    /* in zephyr\dts\arm\st\g4\stm32g4.dtsi:671 */
		ts-cal1-temp = < 0x1e >;          /* in zephyr\dts\arm\st\g4\stm32g4.dtsi:672 */
		ts-cal2-temp = < 0x82 >;          /* in zephyr\dts\arm\st\g4\stm32g4.dtsi:673 */
		ts-cal-vrefanalog = < 0xbb8 >;    /* in zephyr\dts\arm\st\g4\stm32g4.dtsi:674 */
		io-channels = < &adc1 0x10 >;     /* in zephyr\dts\arm\st\g4\stm32g4.dtsi:675 */
		status = "disabled";              /* in zephyr\dts\arm\st\g4\stm32g4.dtsi:676 */
	};

	/* node '/vref' defined in zephyr\dts\arm\st\g4\stm32g4.dtsi:679 */
	vref: vref {
		compatible = "st,stm32-vref";      /* in zephyr\dts\arm\st\g4\stm32g4.dtsi:680 */
		vrefint-cal-addr = < 0x1fff75aa >; /* in zephyr\dts\arm\st\g4\stm32g4.dtsi:681 */
		vrefint-cal-mv = < 0xbb8 >;        /* in zephyr\dts\arm\st\g4\stm32g4.dtsi:682 */
		io-channels = < &adc1 0x12 >;      /* in zephyr\dts\arm\st\g4\stm32g4.dtsi:683 */
		status = "disabled";               /* in zephyr\dts\arm\st\g4\stm32g4.dtsi:684 */
	};

	/* node '/vbat' defined in zephyr\dts\arm\st\g4\stm32g4.dtsi:687 */
	vbat: vbat {
		compatible = "st,stm32-vbat"; /* in zephyr\dts\arm\st\g4\stm32g4.dtsi:688 */
		ratio = < 0x3 >;              /* in zephyr\dts\arm\st\g4\stm32g4.dtsi:689 */
		io-channels = < &adc1 0x11 >; /* in zephyr\dts\arm\st\g4\stm32g4.dtsi:690 */
		status = "disabled";          /* in zephyr\dts\arm\st\g4\stm32g4.dtsi:691 */
	};

	/* node '/usbphy' defined in zephyr\dts\arm\st\g4\stm32g4.dtsi:694 */
	usb_fs_phy: usbphy {
		compatible = "usb-nop-xceiv"; /* in zephyr\dts\arm\st\g4\stm32g4.dtsi:695 */
		#phy-cells = < 0x0 >;         /* in zephyr\dts\arm\st\g4\stm32g4.dtsi:696 */
		phandle = < 0x19 >;           /* in zephyr\dts\arm\st\g4\stm32g4.dtsi:625 */
	};

	/* node '/smbus1' defined in zephyr\dts\arm\st\g4\stm32g4.dtsi:699 */
	smbus1: smbus1 {
		compatible = "st,stm32-smbus"; /* in zephyr\dts\arm\st\g4\stm32g4.dtsi:700 */
		#address-cells = < 0x1 >;      /* in zephyr\dts\arm\st\g4\stm32g4.dtsi:701 */
		#size-cells = < 0x0 >;         /* in zephyr\dts\arm\st\g4\stm32g4.dtsi:702 */
		i2c = < &i2c1 >;               /* in zephyr\dts\arm\st\g4\stm32g4.dtsi:703 */
		status = "disabled";           /* in zephyr\dts\arm\st\g4\stm32g4.dtsi:704 */
	};

	/* node '/smbus2' defined in zephyr\dts\arm\st\g4\stm32g4.dtsi:707 */
	smbus2: smbus2 {
		compatible = "st,stm32-smbus"; /* in zephyr\dts\arm\st\g4\stm32g4.dtsi:708 */
		#address-cells = < 0x1 >;      /* in zephyr\dts\arm\st\g4\stm32g4.dtsi:709 */
		#size-cells = < 0x0 >;         /* in zephyr\dts\arm\st\g4\stm32g4.dtsi:710 */
		i2c = < &i2c2 >;               /* in zephyr\dts\arm\st\g4\stm32g4.dtsi:711 */
		status = "disabled";           /* in zephyr\dts\arm\st\g4\stm32g4.dtsi:712 */
	};

	/* node '/smbus3' defined in zephyr\dts\arm\st\g4\stm32g4.dtsi:715 */
	smbus3: smbus3 {
		compatible = "st,stm32-smbus"; /* in zephyr\dts\arm\st\g4\stm32g4.dtsi:716 */
		#address-cells = < 0x1 >;      /* in zephyr\dts\arm\st\g4\stm32g4.dtsi:717 */
		#size-cells = < 0x0 >;         /* in zephyr\dts\arm\st\g4\stm32g4.dtsi:718 */
		i2c = < &i2c3 >;               /* in zephyr\dts\arm\st\g4\stm32g4.dtsi:719 */
		status = "disabled";           /* in zephyr\dts\arm\st\g4\stm32g4.dtsi:720 */
	};

	/* node '/connector' defined in zephyr\boards\st\nucleo_g431rb\arduino_r3_connector.dtsi:8 */
	arduino_header: connector {
		compatible = "arduino-header-r3";          /* in zephyr\boards\st\nucleo_g431rb\arduino_r3_connector.dtsi:9 */
		#gpio-cells = < 0x2 >;                     /* in zephyr\boards\st\nucleo_g431rb\arduino_r3_connector.dtsi:10 */
		gpio-map-mask = < 0xffffffff 0xffffffc0 >; /* in zephyr\boards\st\nucleo_g431rb\arduino_r3_connector.dtsi:11 */
		gpio-map-pass-thru = < 0x0 0x3f >;         /* in zephyr\boards\st\nucleo_g431rb\arduino_r3_connector.dtsi:12 */
		gpio-map = < 0x0 0x0 &gpioa 0x0 0x0 >,
		           < 0x1 0x0 &gpioa 0x1 0x0 >,
		           < 0x2 0x0 &gpioa 0x4 0x0 >,
		           < 0x3 0x0 &gpiob 0x0 0x0 >,
		           < 0x4 0x0 &gpioc 0x1 0x0 >,
		           < 0x5 0x0 &gpioc 0x0 0x0 >,
		           < 0x6 0x0 &gpioc 0x5 0x0 >,
		           < 0x7 0x0 &gpioc 0x4 0x0 >,
		           < 0x8 0x0 &gpioa 0xa 0x0 >,
		           < 0x9 0x0 &gpiob 0x3 0x0 >,
		           < 0xa 0x0 &gpiob 0x5 0x0 >,
		           < 0xb 0x0 &gpiob 0x4 0x0 >,
		           < 0xc 0x0 &gpiob 0xa 0x0 >,
		           < 0xd 0x0 &gpioa 0x8 0x0 >,
		           < 0xe 0x0 &gpioa 0x9 0x0 >,
		           < 0xf 0x0 &gpioc 0x7 0x0 >,
		           < 0x10 0x0 &gpiob 0x6 0x0 >,
		           < 0x11 0x0 &gpioa 0x7 0x0 >,
		           < 0x12 0x0 &gpioa 0x6 0x0 >,
		           < 0x13 0x0 &gpioa 0x5 0x0 >,
		           < 0x14 0x0 &gpiob 0x9 0x0 >,
		           < 0x15 0x0 &gpiob 0x8 0x0 >;    /* in zephyr\boards\st\nucleo_g431rb\arduino_r3_connector.dtsi:13 */
	};

	/* node '/st-morpho-header' defined in zephyr\boards\st\nucleo_g431rb\st_morpho_connector.dtsi:10 */
	st_morpho_header: st-morpho-header {
		compatible = "st-morpho-header";        /* in zephyr\boards\st\nucleo_g431rb\st_morpho_connector.dtsi:11 */
		#gpio-cells = < 0x2 >;                  /* in zephyr\boards\st\nucleo_g431rb\st_morpho_connector.dtsi:12 */
		gpio-map-mask = < 0xff 0x0 >;           /* in zephyr\boards\st\nucleo_g431rb\st_morpho_connector.dtsi:13 */
		gpio-map-pass-thru = < 0x0 0x3f >;      /* in zephyr\boards\st\nucleo_g431rb\st_morpho_connector.dtsi:14 */
		gpio-map = < 0x0 0x0 &gpioc 0xa 0x0 >,
		           < 0x1 0x0 &gpioc 0xb 0x0 >,
		           < 0x2 0x0 &gpioc 0xc 0x0 >,
		           < 0x3 0x0 &gpiod 0x2 0x0 >,
		           < 0xc 0x0 &gpioa 0xd 0x0 >,
		           < 0xe 0x0 &gpioa 0xe 0x0 >,
		           < 0x10 0x0 &gpioa 0xf 0x0 >,
		           < 0x14 0x0 &gpiob 0x7 0x0 >,
		           < 0x16 0x0 &gpioc 0xd 0x0 >,
		           < 0x18 0x0 &gpioc 0xe 0x0 >,
		           < 0x1a 0x0 &gpioc 0xf 0x0 >,
		           < 0x1b 0x0 &gpioa 0x0 0x0 >,
		           < 0x1c 0x0 &gpiof 0x0 0x0 >,
		           < 0x1d 0x0 &gpioa 0x1 0x0 >,
		           < 0x1e 0x0 &gpiof 0x1 0x0 >,
		           < 0x1f 0x0 &gpioa 0x4 0x0 >,
		           < 0x21 0x0 &gpiob 0x0 0x0 >,
		           < 0x22 0x0 &gpioc 0x2 0x0 >,
		           < 0x23 0x0 &gpioc 0x1 0x0 >,
		           < 0x24 0x0 &gpioc 0x3 0x0 >,
		           < 0x25 0x0 &gpioc 0x0 0x0 >,
		           < 0x48 0x0 &gpioc 0x9 0x0 >,
		           < 0x49 0x0 &gpioc 0x8 0x0 >,
		           < 0x4a 0x0 &gpiob 0x8 0x0 >,
		           < 0x4b 0x0 &gpioc 0x6 0x0 >,
		           < 0x4c 0x0 &gpiob 0x9 0x0 >,
		           < 0x4d 0x0 &gpioc 0x5 0x0 >,
		           < 0x52 0x0 &gpiob 0xd 0x0 >,
		           < 0x53 0x0 &gpioa 0xc 0x0 >,
		           < 0x54 0x0 &gpiob 0xe 0x0 >,
		           < 0x55 0x0 &gpioa 0xb 0x0 >,
		           < 0x56 0x0 &gpiob 0xf 0x0 >,
		           < 0x57 0x0 &gpiob 0xc 0x0 >,
		           < 0x58 0x0 &gpiob 0x6 0x0 >,
		           < 0x59 0x0 &gpiob 0xb 0x0 >,
		           < 0x5a 0x0 &gpioc 0x7 0x0 >,
		           < 0x5c 0x0 &gpioa 0x9 0x0 >,
		           < 0x5d 0x0 &gpiob 0x2 0x0 >,
		           < 0x5e 0x0 &gpioa 0x8 0x0 >,
		           < 0x5f 0x0 &gpiob 0x1 0x0 >,
		           < 0x60 0x0 &gpiob 0xa 0x0 >,
		           < 0x61 0x0 &gpioa 0x7 0x0 >,
		           < 0x62 0x0 &gpiob 0x4 0x0 >,
		           < 0x63 0x0 &gpioa 0x6 0x0 >,
		           < 0x64 0x0 &gpiob 0x5 0x0 >,
		           < 0x65 0x0 &gpioa 0x5 0x0 >,
		           < 0x66 0x0 &gpiob 0x3 0x0 >,
		           < 0x68 0x0 &gpioa 0xa 0x0 >,
		           < 0x69 0x0 &gpioc 0x4 0x0 >,
		           < 0x6a 0x0 &gpioa 0x2 0x0 >,
		           < 0x6c 0x0 &gpioa 0x3 0x0 >; /* in zephyr\boards\st\nucleo_g431rb\st_morpho_connector.dtsi:15 */
	};

	/* node '/leds' defined in zephyr\boards\st\nucleo_g431rb\nucleo_g431rb.dts:26 */
	leds: leds {
		compatible = "gpio-leds"; /* in zephyr\boards\st\nucleo_g431rb\nucleo_g431rb.dts:27 */

		/* node '/leds/led_0' defined in zephyr\boards\st\nucleo_g431rb\nucleo_g431rb.dts:29 */
		green_led: led_0 {
			gpios = < &gpioa 0x5 0x0 >; /* in zephyr\boards\st\nucleo_g431rb\nucleo_g431rb.dts:30 */
			label = "User LD2";         /* in zephyr\boards\st\nucleo_g431rb\nucleo_g431rb.dts:31 */
		};
	};

	/* node '/pwmleds' defined in zephyr\boards\st\nucleo_g431rb\nucleo_g431rb.dts:35 */
	pwmleds {
		compatible = "pwm-leds"; /* in zephyr\boards\st\nucleo_g431rb\nucleo_g431rb.dts:36 */

		/* node '/pwmleds/green_pwm_led' defined in zephyr\boards\st\nucleo_g431rb\nucleo_g431rb.dts:38 */
		green_pwm_led: green_pwm_led {
			pwms = < &pwm2 0x1 0x1312d00 0x0 >; /* in zephyr\boards\st\nucleo_g431rb\nucleo_g431rb.dts:39 */
		};
	};

	/* node '/gpio_keys' defined in zephyr\boards\st\nucleo_g431rb\nucleo_g431rb.dts:43 */
	gpio_keys {
		compatible = "gpio-keys"; /* in zephyr\boards\st\nucleo_g431rb\nucleo_g431rb.dts:44 */

		/* node '/gpio_keys/button' defined in zephyr\boards\st\nucleo_g431rb\nucleo_g431rb.dts:46 */
		user_button: button {
			label = "User";             /* in zephyr\boards\st\nucleo_g431rb\nucleo_g431rb.dts:47 */
			gpios = < &gpioc 0xd 0x0 >; /* in zephyr\boards\st\nucleo_g431rb\nucleo_g431rb.dts:48 */
			zephyr,code = < 0xb >;      /* in zephyr\boards\st\nucleo_g431rb\nucleo_g431rb.dts:49 */
		};
	};
};
